[part 1 of 3: packages /Nexteer/NvMProxy_swc/DataTypes to /Nexteer/NvMProxy_swc/ComponentTypes]
AUTOSAR XML (schema 4-1-2)
package /Nexteer/NvMProxy_swc/DataTypes
  impl type NvM_BlockIdType: category=VALUE, base-type=NvM_BlockIdType, range raw 1..32767
  impl type NvM_RequestResultType: category=VALUE, base-type=NvM_RequestResultType, compu {0=NVM_REQ_OK, 1=NVM_REQ_NOT_OK, 2=NVM_REQ_PENDING, 3=NVM_REQ_INTEGRITY_FAILED, 4=NVM_REQ_BLOCK_SKIPPED, 5=NVM_REQ_NV_INVALIDATED, 6=NVM_REQ_CANCELED, 7=NVM_REQ_REDUNDANCY_FAILED, 8=NVM_REQ_RESTORED_FROM_ROM}
package /Nexteer/NvMProxy_swc/DataTypes/BaseTypes
  base type NvM_BlockIdType: category=FIXED_LENGTH, base-type-size=16, base-type-encoding=NONE, native-declaration=uint16
  base type NvM_RequestResultType: category=FIXED_LENGTH, base-type-size=8, base-type-encoding=NONE, native-declaration=uint8
package /Nexteer/NvMProxy_swc/Interfaces
  5 x client server interface, all with is-service=true:
    NvMAdministration
      operation SetBlockProtection: possible-error=NvMAdministration/E_NOT_OK
        arg ProtectionEnabled_Arg: type=boolean, direction=IN
      error E_NOT_OK: error-code=1
    NvMService_AC3_SRBS
      6 x operation, all with possible-error=NvMService_AC3_SRBS/E_NOT_OK:
        EraseBlock
        GetErrorStatus
          arg ErrorStatus_Arg: type=NvM_RequestResultType, direction=OUT
        InvalidateNvBlock
        ReadBlock
          arg DstPtr_Arg: type=dtRef_VOID, direction=IN
        SetRamBlockStatus
          arg RamBlockStatus_Arg: type=boolean, direction=IN
        WriteBlock
          arg SrcPtr_Arg: type=dtRef_const_VOID, direction=IN
      error E_NOT_OK: error-code=1
    NvMService_AC3_SRBS_Defs
      7 x operation, all with possible-error=NvMService_AC3_SRBS_Defs/E_NOT_OK:
        EraseBlock
        GetErrorStatus
          arg ErrorStatus_Arg: type=NvM_RequestResultType, direction=OUT
        InvalidateNvBlock
        ReadBlock
          arg DstPtr_Arg: type=dtRef_VOID, direction=IN
        RestoreBlockDefaults
          arg DstPtr_Arg: type=dtRef_VOID, direction=IN
        SetRamBlockStatus
          arg RamBlockStatus_Arg: type=boolean, direction=IN
        WriteBlock
          arg SrcPtr_Arg: type=dtRef_const_VOID, direction=IN
      error E_NOT_OK: error-code=1
    NvMService_AC3_SRBS_DS
      8 x operation, all with possible-error=NvMService_AC3_SRBS_DS/E_NOT_OK:
        EraseBlock
        GetDataIndex
          arg DataIndex_Arg: type=uint8, direction=OUT
        GetErrorStatus
          arg ErrorStatus_Arg: type=NvM_RequestResultType, direction=OUT
        InvalidateNvBlock
        ReadBlock
          arg DstPtr_Arg: type=dtRef_VOID, direction=IN
        SetDataIndex
          arg DataIndex_Arg: type=uint8, direction=IN
        SetRamBlockStatus
          arg RamBlockStatus_Arg: type=boolean, direction=IN
        WriteBlock
          arg SrcPtr_Arg: type=dtRef_const_VOID, direction=IN
      error E_NOT_OK: error-code=1
    NvMService_AC3_SRBS_DS_Defs
      9 x operation, all with possible-error=NvMService_AC3_SRBS_DS_Defs/E_NOT_OK:
        EraseBlock
        GetDataIndex
          arg DataIndex_Arg: type=uint8, direction=OUT
        GetErrorStatus
          arg ErrorStatus_Arg: type=NvM_RequestResultType, direction=OUT
        InvalidateNvBlock
        ReadBlock
          arg DstPtr_Arg: type=dtRef_VOID, direction=IN
        RestoreBlockDefaults
          arg DstPtr_Arg: type=dtRef_VOID, direction=IN
        SetDataIndex
          arg DataIndex_Arg: type=uint8, direction=IN
        SetRamBlockStatus
          arg RamBlockStatus_Arg: type=boolean, direction=IN
        WriteBlock
          arg SrcPtr_Arg: type=dtRef_const_VOID, direction=IN
      error E_NOT_OK: error-code=1
package /Nexteer/NvMProxy_swc/ComponentTypes
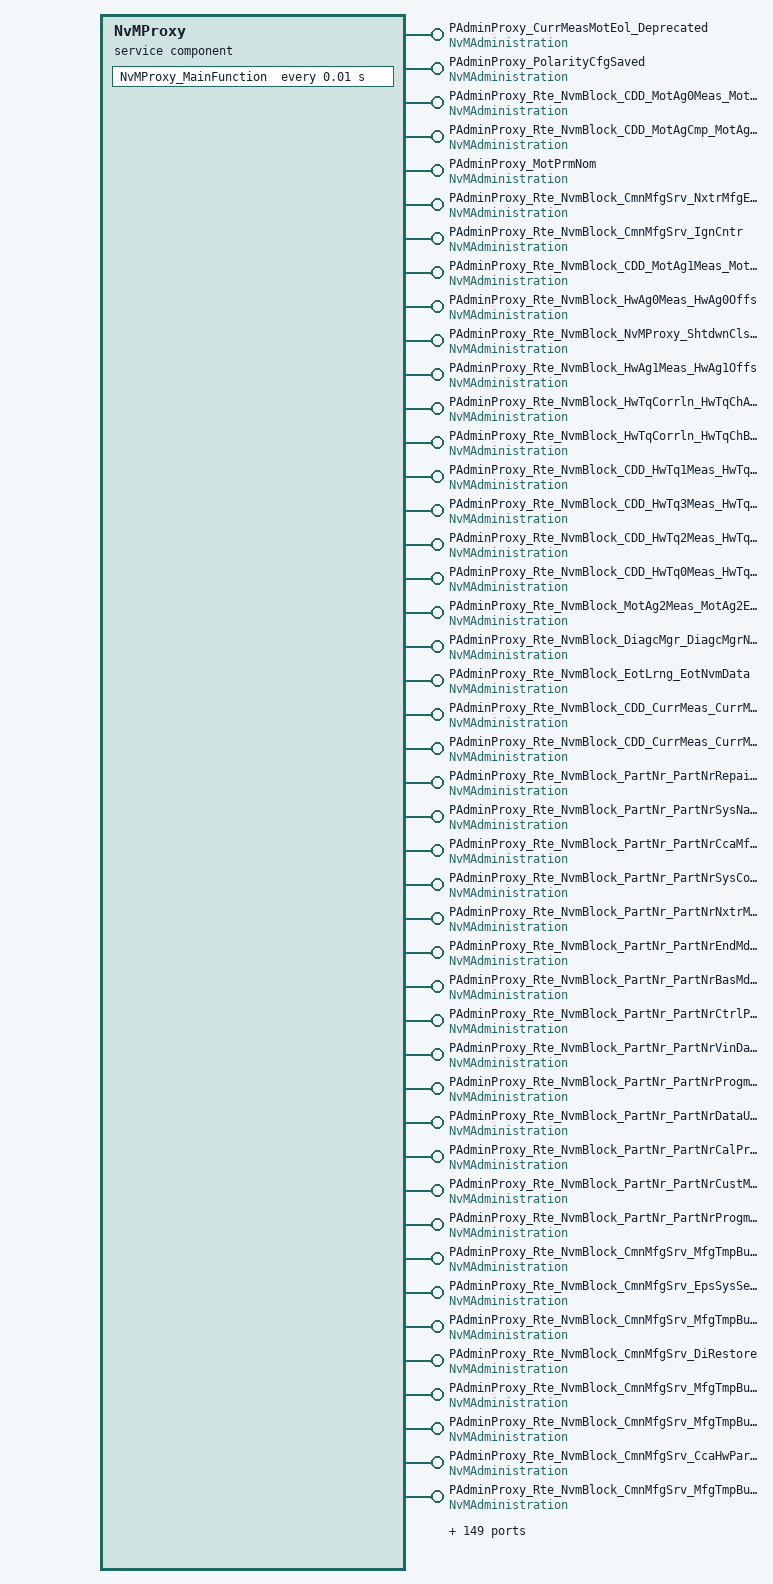
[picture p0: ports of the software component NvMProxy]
  service sw component type NvMProxy
    232 x provide port:
      PAdminProxy_CurrMeasMotEol_Deprecated: server-com-spec{operation=SetBlockProtection, queue-length=1}, provided-interface=NvMAdministration
      PAdminProxy_PolarityCfgSaved: server-com-spec{operation=SetBlockProtection, queue-length=1}, provided-interface=NvMAdministration
      PAdminProxy_Rte_NvmBlock_CDD_MotAg0Meas_MotAg0CoeffTbl: server-com-spec{operation=SetBlockProtection, queue-length=1}, provided-interface=NvMAdministration
      PAdminProxy_Rte_NvmBlock_CDD_MotAgCmp_MotAgCmpMotAgBackEmf: server-com-spec{operation=SetBlockProtection, queue-length=1}, provided-interface=NvMAdministration
      PAdminProxy_MotPrmNom: server-com-spec{operation=SetBlockProtection, queue-length=1}, provided-interface=NvMAdministration
      PAdminProxy_Rte_NvmBlock_CmnMfgSrv_NxtrMfgEnaCntr: server-com-spec{operation=SetBlockProtection, queue-length=1}, provided-interface=NvMAdministration
      PAdminProxy_Rte_NvmBlock_CmnMfgSrv_IgnCntr: server-com-spec{operation=SetBlockProtection, queue-length=1}, provided-interface=NvMAdministration
      PAdminProxy_Rte_NvmBlock_CDD_MotAg1Meas_MotAg1CoeffTbl: server-com-spec{operation=SetBlockProtection, queue-length=1}, provided-interface=NvMAdministration
      PAdminProxy_Rte_NvmBlock_HwAg0Meas_HwAg0Offs: server-com-spec{operation=SetBlockProtection, queue-length=1}, provided-interface=NvMAdministration
      PAdminProxy_Rte_NvmBlock_NvMProxy_ShtdwnClsChk: server-com-spec{operation=SetBlockProtection, queue-length=1}, provided-interface=NvMAdministration
      PAdminProxy_Rte_NvmBlock_HwAg1Meas_HwAg1Offs: server-com-spec{operation=SetBlockProtection, queue-length=1}, provided-interface=NvMAdministration
      PAdminProxy_Rte_NvmBlock_HwTqCorrln_HwTqChACmnModCmpLpFilSt: server-com-spec{operation=SetBlockProtection, queue-length=1}, provided-interface=NvMAdministration
      PAdminProxy_Rte_NvmBlock_HwTqCorrln_HwTqChBCmnModCmpLpFilSt: server-com-spec{operation=SetBlockProtection, queue-length=1}, provided-interface=NvMAdministration
      PAdminProxy_Rte_NvmBlock_CDD_HwTq1Meas_HwTq1Offs: server-com-spec{operation=SetBlockProtection, queue-length=1}, provided-interface=NvMAdministration
      PAdminProxy_Rte_NvmBlock_CDD_HwTq3Meas_HwTq3Offs: server-com-spec{operation=SetBlockProtection, queue-length=1}, provided-interface=NvMAdministration
      PAdminProxy_Rte_NvmBlock_CDD_HwTq2Meas_HwTq2Offs: server-com-spec{operation=SetBlockProtection, queue-length=1}, provided-interface=NvMAdministration
      PAdminProxy_Rte_NvmBlock_CDD_HwTq0Meas_HwTq0Offs: server-com-spec{operation=SetBlockProtection, queue-length=1}, provided-interface=NvMAdministration
      PAdminProxy_Rte_NvmBlock_MotAg2Meas_MotAg2EolPrm: server-com-spec{operation=SetBlockProtection, queue-length=1}, provided-interface=NvMAdministration
      PAdminProxy_Rte_NvmBlock_DiagcMgr_DiagcMgrNtcFltAry: server-com-spec{operation=SetBlockProtection, queue-length=1}, provided-interface=NvMAdministration
      PAdminProxy_Rte_NvmBlock_EotLrng_EotNvmData: server-com-spec{operation=SetBlockProtection, queue-length=1}, provided-interface=NvMAdministration
      PAdminProxy_Rte_NvmBlock_CDD_CurrMeas_CurrMeasEolOffsCalSet: server-com-spec{operation=SetBlockProtection, queue-length=1}, provided-interface=NvMAdministration
      PAdminProxy_Rte_NvmBlock_CDD_CurrMeas_CurrMeasEolGainCalSet: server-com-spec{operation=SetBlockProtection, queue-length=1}, provided-interface=NvMAdministration
      PAdminProxy_Rte_NvmBlock_PartNr_PartNrRepairShopCod: server-com-spec{operation=SetBlockProtection, queue-length=1}, provided-interface=NvMAdministration
      PAdminProxy_Rte_NvmBlock_PartNr_PartNrSysName: server-com-spec{operation=SetBlockProtection, queue-length=1}, provided-interface=NvMAdministration
      PAdminProxy_Rte_NvmBlock_PartNr_PartNrCcaMfgTrakg: server-com-spec{operation=SetBlockProtection, queue-length=1}, provided-interface=NvMAdministration
      PAdminProxy_Rte_NvmBlock_PartNr_PartNrSysCodVersNr: server-com-spec{operation=SetBlockProtection, queue-length=1}, provided-interface=NvMAdministration
      PAdminProxy_Rte_NvmBlock_PartNr_PartNrNxtrMfgTrakg: server-com-spec{operation=SetBlockProtection, queue-length=1}, provided-interface=NvMAdministration
      PAdminProxy_Rte_NvmBlock_PartNr_PartNrEndMdlPartNr: server-com-spec{operation=SetBlockProtection, queue-length=1}, provided-interface=NvMAdministration
      PAdminProxy_Rte_NvmBlock_PartNr_PartNrBasMdlPartNr: server-com-spec{operation=SetBlockProtection, queue-length=1}, provided-interface=NvMAdministration
      PAdminProxy_Rte_NvmBlock_PartNr_PartNrCtrlPidSeedKey: server-com-spec{operation=SetBlockProtection, queue-length=1}, provided-interface=NvMAdministration
      PAdminProxy_Rte_NvmBlock_PartNr_PartNrVinData: server-com-spec{operation=SetBlockProtection, queue-length=1}, provided-interface=NvMAdministration
      PAdminProxy_Rte_NvmBlock_PartNr_PartNrProgmDate: server-com-spec{operation=SetBlockProtection, queue-length=1}, provided-interface=NvMAdministration
      PAdminProxy_Rte_NvmBlock_PartNr_PartNrDataUniversalNrSysId: server-com-spec{operation=SetBlockProtection, queue-length=1}, provided-interface=NvMAdministration
      PAdminProxy_Rte_NvmBlock_PartNr_PartNrCalProgdSts: server-com-spec{operation=SetBlockProtection, queue-length=1}, provided-interface=NvMAdministration
      PAdminProxy_Rte_NvmBlock_PartNr_PartNrCustMfgEnaCntr: server-com-spec{operation=SetBlockProtection, queue-length=1}, provided-interface=NvMAdministration
      PAdminProxy_Rte_NvmBlock_PartNr_PartNrProgmSessionSeedKey: server-com-spec{operation=SetBlockProtection, queue-length=1}, provided-interface=NvMAdministration
      PAdminProxy_Rte_NvmBlock_CmnMfgSrv_MfgTmpBuf4: server-com-spec{operation=SetBlockProtection, queue-length=1}, provided-interface=NvMAdministration
      PAdminProxy_Rte_NvmBlock_CmnMfgSrv_EpsSysSerlNr: server-com-spec{operation=SetBlockProtection, queue-length=1}, provided-interface=NvMAdministration
      PAdminProxy_Rte_NvmBlock_CmnMfgSrv_MfgTmpBuf3: server-com-spec{operation=SetBlockProtection, queue-length=1}, provided-interface=NvMAdministration
      PAdminProxy_Rte_NvmBlock_CmnMfgSrv_DiRestore: server-com-spec{operation=SetBlockProtection, queue-length=1}, provided-interface=NvMAdministration
      PAdminProxy_Rte_NvmBlock_CmnMfgSrv_MfgTmpBuf2: server-com-spec{operation=SetBlockProtection, queue-length=1}, provided-interface=NvMAdministration
      PAdminProxy_Rte_NvmBlock_CmnMfgSrv_MfgTmpBuf1: server-com-spec{operation=SetBlockProtection, queue-length=1}, provided-interface=NvMAdministration
      PAdminProxy_Rte_NvmBlock_CmnMfgSrv_CcaHwPartNr: server-com-spec{operation=SetBlockProtection, queue-length=1}, provided-interface=NvMAdministration
      PAdminProxy_Rte_NvmBlock_CmnMfgSrv_MfgTmpBuf0: server-com-spec{operation=SetBlockProtection, queue-length=1}, provided-interface=NvMAdministration
      PAdminProxy_Rte_NvmBlock_CmnMfgSrv_CcaSerlNr: server-com-spec{operation=SetBlockProtection, queue-length=1}, provided-interface=NvMAdministration
      PAdminProxy_Rte_NvmBlock_DutyCycThermProtn_FilStVal: server-com-spec{operation=SetBlockProtection, queue-length=1}, provided-interface=NvMAdministration
      PAdminProxy_Rte_NvmBlock_PullCmpActv_PullCmpLongTerm: server-com-spec{operation=SetBlockProtection, queue-length=1}, provided-interface=NvMAdministration
      PAdminProxy_Rte_NvmBlock_MotTqCmdSca_MotTqScaFac: server-com-spec{operation=SetBlockProtection, queue-length=1}, provided-interface=NvMAdministration
      PAdminProxy_Rte_NvmBlock_SnsrOffsLrng_SnsrOffsLrnd: server-com-spec{operation=SetBlockProtection, queue-length=1}, provided-interface=NvMAdministration
      PAdminProxy_Rte_NvmBlock_GmOvrlStMgr_GmLoaIgnCntr: server-com-spec{operation=SetBlockProtection, queue-length=1}, provided-interface=NvMAdministration
      PAdminProxy_Rte_NvmBlock_MotRplCoggCfg_MotRplCoggPrm: server-com-spec{operation=SetBlockProtection, queue-length=1}, provided-interface=NvMAdministration
      PAdminProxy_Rte_NvmBlock_CDD_MotRplCoggCmd_MotCoggCmdY: server-com-spec{operation=SetBlockProtection, queue-length=1}, provided-interface=NvMAdministration
      PAdminProxy_Rte_NvmBlock_StHlthSigStc_SigStcHistDataAry: server-com-spec{operation=SetBlockProtection, queue-length=1}, provided-interface=NvMAdministration
      PAdminProxy_Rte_NvmBlock_HwAgVehCentrTrim_HwAgTrimVal_Deprecated: server-com-spec{operation=SetBlockProtection, queue-length=1}, provided-interface=NvMAdministration
      PAdminProxy_Rte_NvmBlock_WhlImbRejctn_MaxCompPerc_Deprecated: server-com-spec{operation=SetBlockProtection, queue-length=1}, provided-interface=NvMAdministration
      PAdminProxy_Rte_NvmBlock_WhlImbRejctn_ActvCmpBand3_Deprecated: server-com-spec{operation=SetBlockProtection, queue-length=1}, provided-interface=NvMAdministration
      PAdminProxy_Rte_NvmBlock_WhlImbRejctn_ActvCmpBand1_Deprecated: server-com-spec{operation=SetBlockProtection, queue-length=1}, provided-interface=NvMAdministration
      PAdminProxy_Rte_NvmBlock_WhlImbRejctn_RiPeakPrev_Deprecated: server-com-spec{operation=SetBlockProtection, queue-length=1}, provided-interface=NvMAdministration
      PAdminProxy_Rte_NvmBlock_WhlImbRejctn_LePeakPrev_Deprecated: server-com-spec{operation=SetBlockProtection, queue-length=1}, provided-interface=NvMAdministration
      PAdminProxy_Rte_NvmBlock_WhlImbRejctn_ActvCmpBand2_Deprecated: server-com-spec{operation=SetBlockProtection, queue-length=1}, provided-interface=NvMAdministration
      PAdminProxy_Rte_NvmBlock_HwAgVehCentrTrim_HwAgTrimData: server-com-spec{operation=SetBlockProtection, queue-length=1}, provided-interface=NvMAdministration
      PAdminProxy_Rte_NvmBlock_SysFricLrng_FricNonLrngData: server-com-spec{operation=SetBlockProtection, queue-length=1}, provided-interface=NvMAdministration
      PAdminProxy_Rte_NvmBlock_SysFricLrng_FricLrngData: server-com-spec{operation=SetBlockProtection, queue-length=1}, provided-interface=NvMAdministration
      PAdminProxy_Rte_NvmBlock_Bootloader_EcuId: server-com-spec{operation=SetBlockProtection, queue-length=1}, provided-interface=NvMAdministration
      PAdminProxy_Rte_NvmBlock_Bootloader_NbId: server-com-spec{operation=SetBlockProtection, queue-length=1}, provided-interface=NvMAdministration
      PAdminProxy_Rte_NvmBlock_Bootloader_SBAT: server-com-spec{operation=SetBlockProtection, queue-length=1}, provided-interface=NvMAdministration
      PAdminProxy_DemAdminDataBlock: server-com-spec{operation=SetBlockProtection, queue-length=1}, provided-interface=NvMAdministration
      PAdminProxy_DemStatusDataBlock: server-com-spec{operation=SetBlockProtection, queue-length=1}, provided-interface=NvMAdministration
      PAdminProxy_DemPrimaryDataBlock{0..39}: server-com-spec{operation=SetBlockProtection, queue-length=1}, provided-interface=NvMAdministration
      PAdminProxy_Rte_NvmBlock_CustDiagc_GmIgnCntr: server-com-spec{operation=SetBlockProtection, queue-length=1}, provided-interface=NvMAdministration
      PAdminProxy_Rte_NvmBlock_GmMsg778BusHiSpd_DtcTrigStsAry: server-com-spec{operation=SetBlockProtection, queue-length=1}, provided-interface=NvMAdministration
      PAdminProxy_SnpshtDataAry: server-com-spec{operation=SetBlockProtection, queue-length=1}, provided-interface=NvMAdministration
      PAdminProxy_Rte_NvmBlock_HwAgSnsrls_StordLstPrm: server-com-spec{operation=SetBlockProtection, queue-length=1}, provided-interface=NvMAdministration
      PAdminProxy_Rte_NvmBlock_EotLrng_MaxHwAgCwAndCcw_Deprecated: server-com-spec{operation=SetBlockProtection, queue-length=1}, provided-interface=NvMAdministration
      PAdminProxy_Rte_NvmBlock_CmnMfgSrv_SeedKey: server-com-spec{operation=SetBlockProtection, queue-length=1}, provided-interface=NvMAdministration
      PAdminProxy_Rte_NvmBlock_EotLrng_MaxHwAgCwAndCcw: server-com-spec{operation=SetBlockProtection, queue-length=1}, provided-interface=NvMAdministration
      PAdminProxy_Rte_NvmBlock_WhlImbRejctn_CmpPeakData: server-com-spec{operation=SetBlockProtection, queue-length=1}, provided-interface=NvMAdministration
      PSProxy_Rte_NvmBlock_CDD_MotAg0Meas_MotAg0CoeffTbl: provided-interface=NvMService_AC3_SRBS_Defs
        provided-com-specs:
          operation=NvMService_AC3_SRBS_Defs/EraseBlock, queue-length=1
          operation=NvMService_AC3_SRBS_Defs/GetErrorStatus, queue-length=1
          operation=NvMService_AC3_SRBS_Defs/InvalidateNvBlock, queue-length=1
          operation=NvMService_AC3_SRBS_Defs/ReadBlock, queue-length=1
          operation=NvMService_AC3_SRBS_Defs/RestoreBlockDefaults, queue-length=1
          operation=NvMService_AC3_SRBS_Defs/SetRamBlockStatus, queue-length=1
          operation=NvMService_AC3_SRBS_Defs/WriteBlock, queue-length=1
      PSProxy_Rte_NvmBlock_CDD_MotAgCmp_MotAgCmpMotAgBackEmf: provided-interface=NvMService_AC3_SRBS_Defs
        provided-com-specs:
          operation=NvMService_AC3_SRBS_Defs/EraseBlock, queue-length=1
          operation=NvMService_AC3_SRBS_Defs/GetErrorStatus, queue-length=1
          operation=NvMService_AC3_SRBS_Defs/InvalidateNvBlock, queue-length=1
          operation=NvMService_AC3_SRBS_Defs/ReadBlock, queue-length=1
          operation=NvMService_AC3_SRBS_Defs/RestoreBlockDefaults, queue-length=1
          operation=NvMService_AC3_SRBS_Defs/SetRamBlockStatus, queue-length=1
          operation=NvMService_AC3_SRBS_Defs/WriteBlock, queue-length=1
      PSProxy_Rte_NvmBlock_CmnMfgSrv_NxtrMfgEnaCntr: provided-interface=NvMService_AC3_SRBS_Defs
        provided-com-specs:
          operation=NvMService_AC3_SRBS_Defs/EraseBlock, queue-length=1
          operation=NvMService_AC3_SRBS_Defs/GetErrorStatus, queue-length=1
          operation=NvMService_AC3_SRBS_Defs/InvalidateNvBlock, queue-length=1
          operation=NvMService_AC3_SRBS_Defs/ReadBlock, queue-length=1
          operation=NvMService_AC3_SRBS_Defs/RestoreBlockDefaults, queue-length=1
          operation=NvMService_AC3_SRBS_Defs/SetRamBlockStatus, queue-length=1
          operation=NvMService_AC3_SRBS_Defs/WriteBlock, queue-length=1
      PSProxy_Rte_NvmBlock_CmnMfgSrv_IgnCntr: provided-interface=NvMService_AC3_SRBS_Defs
        provided-com-specs:
          operation=NvMService_AC3_SRBS_Defs/EraseBlock, queue-length=1
          operation=NvMService_AC3_SRBS_Defs/GetErrorStatus, queue-length=1
          operation=NvMService_AC3_SRBS_Defs/InvalidateNvBlock, queue-length=1
          operation=NvMService_AC3_SRBS_Defs/ReadBlock, queue-length=1
          operation=NvMService_AC3_SRBS_Defs/RestoreBlockDefaults, queue-length=1
          operation=NvMService_AC3_SRBS_Defs/SetRamBlockStatus, queue-length=1
          operation=NvMService_AC3_SRBS_Defs/WriteBlock, queue-length=1
      PSProxy_Rte_NvmBlock_CDD_MotAg1Meas_MotAg1CoeffTbl: provided-interface=NvMService_AC3_SRBS_Defs
        provided-com-specs:
          operation=NvMService_AC3_SRBS_Defs/EraseBlock, queue-length=1
          operation=NvMService_AC3_SRBS_Defs/GetErrorStatus, queue-length=1
          operation=NvMService_AC3_SRBS_Defs/InvalidateNvBlock, queue-length=1
          operation=NvMService_AC3_SRBS_Defs/ReadBlock, queue-length=1
          operation=NvMService_AC3_SRBS_Defs/RestoreBlockDefaults, queue-length=1
          operation=NvMService_AC3_SRBS_Defs/SetRamBlockStatus, queue-length=1
          operation=NvMService_AC3_SRBS_Defs/WriteBlock, queue-length=1
      PSProxy_Rte_NvmBlock_HwAg0Meas_HwAg0Offs: provided-interface=NvMService_AC3_SRBS_Defs
        provided-com-specs:
          operation=NvMService_AC3_SRBS_Defs/EraseBlock, queue-length=1
          operation=NvMService_AC3_SRBS_Defs/GetErrorStatus, queue-length=1
          operation=NvMService_AC3_SRBS_Defs/InvalidateNvBlock, queue-length=1
          operation=NvMService_AC3_SRBS_Defs/ReadBlock, queue-length=1
          operation=NvMService_AC3_SRBS_Defs/RestoreBlockDefaults, queue-length=1
          operation=NvMService_AC3_SRBS_Defs/SetRamBlockStatus, queue-length=1
          operation=NvMService_AC3_SRBS_Defs/WriteBlock, queue-length=1
      PSProxy_Rte_NvmBlock_HwAg1Meas_HwAg1Offs: provided-interface=NvMService_AC3_SRBS_Defs
        provided-com-specs:
          operation=NvMService_AC3_SRBS_Defs/EraseBlock, queue-length=1
          operation=NvMService_AC3_SRBS_Defs/GetErrorStatus, queue-length=1
          operation=NvMService_AC3_SRBS_Defs/InvalidateNvBlock, queue-length=1
          operation=NvMService_AC3_SRBS_Defs/ReadBlock, queue-length=1
          operation=NvMService_AC3_SRBS_Defs/RestoreBlockDefaults, queue-length=1
          operation=NvMService_AC3_SRBS_Defs/SetRamBlockStatus, queue-length=1
          operation=NvMService_AC3_SRBS_Defs/WriteBlock, queue-length=1
      PSProxy_Rte_NvmBlock_HwTqCorrln_HwTqChACmnModCmpLpFilSt: provided-interface=NvMService_AC3_SRBS_Defs
        provided-com-specs:
          operation=NvMService_AC3_SRBS_Defs/EraseBlock, queue-length=1
          operation=NvMService_AC3_SRBS_Defs/GetErrorStatus, queue-length=1
          operation=NvMService_AC3_SRBS_Defs/InvalidateNvBlock, queue-length=1
          operation=NvMService_AC3_SRBS_Defs/ReadBlock, queue-length=1
          operation=NvMService_AC3_SRBS_Defs/RestoreBlockDefaults, queue-length=1
          operation=NvMService_AC3_SRBS_Defs/SetRamBlockStatus, queue-length=1
          operation=NvMService_AC3_SRBS_Defs/WriteBlock, queue-length=1
      PSProxy_Rte_NvmBlock_HwTqCorrln_HwTqChBCmnModCmpLpFilSt: provided-interface=NvMService_AC3_SRBS_Defs
        provided-com-specs:
          operation=NvMService_AC3_SRBS_Defs/EraseBlock, queue-length=1
          operation=NvMService_AC3_SRBS_Defs/GetErrorStatus, queue-length=1
          operation=NvMService_AC3_SRBS_Defs/InvalidateNvBlock, queue-length=1
          operation=NvMService_AC3_SRBS_Defs/ReadBlock, queue-length=1
          operation=NvMService_AC3_SRBS_Defs/RestoreBlockDefaults, queue-length=1
          operation=NvMService_AC3_SRBS_Defs/SetRamBlockStatus, queue-length=1
          operation=NvMService_AC3_SRBS_Defs/WriteBlock, queue-length=1
      PSProxy_Rte_NvmBlock_CDD_HwTq1Meas_HwTq1Offs: provided-interface=NvMService_AC3_SRBS_Defs
        provided-com-specs:
          operation=NvMService_AC3_SRBS_Defs/EraseBlock, queue-length=1
          operation=NvMService_AC3_SRBS_Defs/GetErrorStatus, queue-length=1
          operation=NvMService_AC3_SRBS_Defs/InvalidateNvBlock, queue-length=1
          operation=NvMService_AC3_SRBS_Defs/ReadBlock, queue-length=1
          operation=NvMService_AC3_SRBS_Defs/RestoreBlockDefaults, queue-length=1
          operation=NvMService_AC3_SRBS_Defs/SetRamBlockStatus, queue-length=1
          operation=NvMService_AC3_SRBS_Defs/WriteBlock, queue-length=1
      PSProxy_Rte_NvmBlock_CDD_HwTq3Meas_HwTq3Offs: provided-interface=NvMService_AC3_SRBS_Defs
        provided-com-specs:
          operation=NvMService_AC3_SRBS_Defs/EraseBlock, queue-length=1
          operation=NvMService_AC3_SRBS_Defs/GetErrorStatus, queue-length=1
          operation=NvMService_AC3_SRBS_Defs/InvalidateNvBlock, queue-length=1
          operation=NvMService_AC3_SRBS_Defs/ReadBlock, queue-length=1
          operation=NvMService_AC3_SRBS_Defs/RestoreBlockDefaults, queue-length=1
          operation=NvMService_AC3_SRBS_Defs/SetRamBlockStatus, queue-length=1
          operation=NvMService_AC3_SRBS_Defs/WriteBlock, queue-length=1
      PSProxy_Rte_NvmBlock_CDD_HwTq2Meas_HwTq2Offs: provided-interface=NvMService_AC3_SRBS_Defs
        provided-com-specs:
          operation=NvMService_AC3_SRBS_Defs/EraseBlock, queue-length=1
          operation=NvMService_AC3_SRBS_Defs/GetErrorStatus, queue-length=1
          operation=NvMService_AC3_SRBS_Defs/InvalidateNvBlock, queue-length=1
          operation=NvMService_AC3_SRBS_Defs/ReadBlock, queue-length=1
          operation=NvMService_AC3_SRBS_Defs/RestoreBlockDefaults, queue-length=1
          operation=NvMService_AC3_SRBS_Defs/SetRamBlockStatus, queue-length=1
          operation=NvMService_AC3_SRBS_Defs/WriteBlock, queue-length=1
      PSProxy_Rte_NvmBlock_CDD_HwTq0Meas_HwTq0Offs: provided-interface=NvMService_AC3_SRBS_Defs
        provided-com-specs:
          operation=NvMService_AC3_SRBS_Defs/EraseBlock, queue-length=1
          operation=NvMService_AC3_SRBS_Defs/GetErrorStatus, queue-length=1
          operation=NvMService_AC3_SRBS_Defs/InvalidateNvBlock, queue-length=1
          operation=NvMService_AC3_SRBS_Defs/ReadBlock, queue-length=1
          operation=NvMService_AC3_SRBS_Defs/RestoreBlockDefaults, queue-length=1
          operation=NvMService_AC3_SRBS_Defs/SetRamBlockStatus, queue-length=1
          operation=NvMService_AC3_SRBS_Defs/WriteBlock, queue-length=1
      PSProxy_Rte_NvmBlock_MotAg2Meas_MotAg2EolPrm: provided-interface=NvMService_AC3_SRBS_Defs
        provided-com-specs:
          operation=NvMService_AC3_SRBS_Defs/EraseBlock, queue-length=1
          operation=NvMService_AC3_SRBS_Defs/GetErrorStatus, queue-length=1
          operation=NvMService_AC3_SRBS_Defs/InvalidateNvBlock, queue-length=1
          operation=NvMService_AC3_SRBS_Defs/ReadBlock, queue-length=1
          operation=NvMService_AC3_SRBS_Defs/RestoreBlockDefaults, queue-length=1
          operation=NvMService_AC3_SRBS_Defs/SetRamBlockStatus, queue-length=1
          operation=NvMService_AC3_SRBS_Defs/WriteBlock, queue-length=1
      PSProxy_Rte_NvmBlock_EotLrng_EotNvmData: provided-interface=NvMService_AC3_SRBS_Defs
        provided-com-specs:
          operation=NvMService_AC3_SRBS_Defs/EraseBlock, queue-length=1
          operation=NvMService_AC3_SRBS_Defs/GetErrorStatus, queue-length=1
          operation=NvMService_AC3_SRBS_Defs/InvalidateNvBlock, queue-length=1
          operation=NvMService_AC3_SRBS_Defs/ReadBlock, queue-length=1
          operation=NvMService_AC3_SRBS_Defs/RestoreBlockDefaults, queue-length=1
          operation=NvMService_AC3_SRBS_Defs/SetRamBlockStatus, queue-length=1
          operation=NvMService_AC3_SRBS_Defs/WriteBlock, queue-length=1
      PSProxy_Rte_NvmBlock_CDD_CurrMeas_CurrMeasEolOffsCalSet: provided-interface=NvMService_AC3_SRBS_Defs
        provided-com-specs:
          operation=NvMService_AC3_SRBS_Defs/EraseBlock, queue-length=1
          operation=NvMService_AC3_SRBS_Defs/GetErrorStatus, queue-length=1
          operation=NvMService_AC3_SRBS_Defs/InvalidateNvBlock, queue-length=1
          operation=NvMService_AC3_SRBS_Defs/ReadBlock, queue-length=1
          operation=NvMService_AC3_SRBS_Defs/RestoreBlockDefaults, queue-length=1
          operation=NvMService_AC3_SRBS_Defs/SetRamBlockStatus, queue-length=1
          operation=NvMService_AC3_SRBS_Defs/WriteBlock, queue-length=1
      PSProxy_Rte_NvmBlock_CDD_CurrMeas_CurrMeasEolGainCalSet: provided-interface=NvMService_AC3_SRBS_Defs
        provided-com-specs:
          operation=NvMService_AC3_SRBS_Defs/EraseBlock, queue-length=1
          operation=NvMService_AC3_SRBS_Defs/GetErrorStatus, queue-length=1
          operation=NvMService_AC3_SRBS_Defs/InvalidateNvBlock, queue-length=1
          operation=NvMService_AC3_SRBS_Defs/ReadBlock, queue-length=1
          operation=NvMService_AC3_SRBS_Defs/RestoreBlockDefaults, queue-length=1
          operation=NvMService_AC3_SRBS_Defs/SetRamBlockStatus, queue-length=1
          operation=NvMService_AC3_SRBS_Defs/WriteBlock, queue-length=1
      PSProxy_Rte_NvmBlock_PartNr_PartNrRepairShopCod: provided-interface=NvMService_AC3_SRBS_Defs
        provided-com-specs:
          operation=NvMService_AC3_SRBS_Defs/EraseBlock, queue-length=1
          operation=NvMService_AC3_SRBS_Defs/GetErrorStatus, queue-length=1
          operation=NvMService_AC3_SRBS_Defs/InvalidateNvBlock, queue-length=1
          operation=NvMService_AC3_SRBS_Defs/ReadBlock, queue-length=1
          operation=NvMService_AC3_SRBS_Defs/RestoreBlockDefaults, queue-length=1
          operation=NvMService_AC3_SRBS_Defs/SetRamBlockStatus, queue-length=1
          operation=NvMService_AC3_SRBS_Defs/WriteBlock, queue-length=1
      PSProxy_Rte_NvmBlock_PartNr_PartNrSysName: provided-interface=NvMService_AC3_SRBS_Defs
        provided-com-specs:
          operation=NvMService_AC3_SRBS_Defs/EraseBlock, queue-length=1
          operation=NvMService_AC3_SRBS_Defs/GetErrorStatus, queue-length=1
          operation=NvMService_AC3_SRBS_Defs/InvalidateNvBlock, queue-length=1
          operation=NvMService_AC3_SRBS_Defs/ReadBlock, queue-length=1
          operation=NvMService_AC3_SRBS_Defs/RestoreBlockDefaults, queue-length=1
          operation=NvMService_AC3_SRBS_Defs/SetRamBlockStatus, queue-length=1
          operation=NvMService_AC3_SRBS_Defs/WriteBlock, queue-length=1
      PSProxy_Rte_NvmBlock_PartNr_PartNrCcaMfgTrakg: provided-interface=NvMService_AC3_SRBS_Defs
        provided-com-specs:
          operation=NvMService_AC3_SRBS_Defs/EraseBlock, queue-length=1
          operation=NvMService_AC3_SRBS_Defs/GetErrorStatus, queue-length=1
          operation=NvMService_AC3_SRBS_Defs/InvalidateNvBlock, queue-length=1
          operation=NvMService_AC3_SRBS_Defs/ReadBlock, queue-length=1
          operation=NvMService_AC3_SRBS_Defs/RestoreBlockDefaults, queue-length=1
          operation=NvMService_AC3_SRBS_Defs/SetRamBlockStatus, queue-length=1
          operation=NvMService_AC3_SRBS_Defs/WriteBlock, queue-length=1
      PSProxy_Rte_NvmBlock_PartNr_PartNrSysCodVersNr: provided-interface=NvMService_AC3_SRBS_Defs
        provided-com-specs:
          operation=NvMService_AC3_SRBS_Defs/EraseBlock, queue-length=1
          operation=NvMService_AC3_SRBS_Defs/GetErrorStatus, queue-length=1
          operation=NvMService_AC3_SRBS_Defs/InvalidateNvBlock, queue-length=1
          operation=NvMService_AC3_SRBS_Defs/ReadBlock, queue-length=1
          operation=NvMService_AC3_SRBS_Defs/RestoreBlockDefaults, queue-length=1
          operation=NvMService_AC3_SRBS_Defs/SetRamBlockStatus, queue-length=1
          operation=NvMService_AC3_SRBS_Defs/WriteBlock, queue-length=1
      PSProxy_Rte_NvmBlock_PartNr_PartNrNxtrMfgTrakg: provided-interface=NvMService_AC3_SRBS_Defs
        provided-com-specs:
          operation=NvMService_AC3_SRBS_Defs/EraseBlock, queue-length=1
          operation=NvMService_AC3_SRBS_Defs/GetErrorStatus, queue-length=1
          operation=NvMService_AC3_SRBS_Defs/InvalidateNvBlock, queue-length=1
          operation=NvMService_AC3_SRBS_Defs/ReadBlock, queue-length=1
          operation=NvMService_AC3_SRBS_Defs/RestoreBlockDefaults, queue-length=1
          operation=NvMService_AC3_SRBS_Defs/SetRamBlockStatus, queue-length=1
          operation=NvMService_AC3_SRBS_Defs/WriteBlock, queue-length=1
      PSProxy_Rte_NvmBlock_PartNr_PartNrEndMdlPartNr: provided-interface=NvMService_AC3_SRBS_Defs
        provided-com-specs:
          operation=NvMService_AC3_SRBS_Defs/EraseBlock, queue-length=1
          operation=NvMService_AC3_SRBS_Defs/GetErrorStatus, queue-length=1
          operation=NvMService_AC3_SRBS_Defs/InvalidateNvBlock, queue-length=1
          operation=NvMService_AC3_SRBS_Defs/ReadBlock, queue-length=1
          operation=NvMService_AC3_SRBS_Defs/RestoreBlockDefaults, queue-length=1
          operation=NvMService_AC3_SRBS_Defs/SetRamBlockStatus, queue-length=1
          operation=NvMService_AC3_SRBS_Defs/WriteBlock, queue-length=1
      PSProxy_Rte_NvmBlock_PartNr_PartNrBasMdlPartNr: provided-interface=NvMService_AC3_SRBS_Defs
        provided-com-specs:
          operation=NvMService_AC3_SRBS_Defs/EraseBlock, queue-length=1
          operation=NvMService_AC3_SRBS_Defs/GetErrorStatus, queue-length=1
          operation=NvMService_AC3_SRBS_Defs/InvalidateNvBlock, queue-length=1
          operation=NvMService_AC3_SRBS_Defs/ReadBlock, queue-length=1
          operation=NvMService_AC3_SRBS_Defs/RestoreBlockDefaults, queue-length=1
          operation=NvMService_AC3_SRBS_Defs/SetRamBlockStatus, queue-length=1
          operation=NvMService_AC3_SRBS_Defs/WriteBlock, queue-length=1
      PSProxy_Rte_NvmBlock_PartNr_PartNrCtrlPidSeedKey: provided-interface=NvMService_AC3_SRBS_Defs
        provided-com-specs:
          operation=NvMService_AC3_SRBS_Defs/EraseBlock, queue-length=1
          operation=NvMService_AC3_SRBS_Defs/GetErrorStatus, queue-length=1
          operation=NvMService_AC3_SRBS_Defs/InvalidateNvBlock, queue-length=1
          operation=NvMService_AC3_SRBS_Defs/ReadBlock, queue-length=1
          operation=NvMService_AC3_SRBS_Defs/RestoreBlockDefaults, queue-length=1
          operation=NvMService_AC3_SRBS_Defs/SetRamBlockStatus, queue-length=1
          operation=NvMService_AC3_SRBS_Defs/WriteBlock, queue-length=1
      PSProxy_Rte_NvmBlock_PartNr_PartNrVinData: provided-interface=NvMService_AC3_SRBS_Defs
        provided-com-specs:
          operation=NvMService_AC3_SRBS_Defs/EraseBlock, queue-length=1
          operation=NvMService_AC3_SRBS_Defs/GetErrorStatus, queue-length=1
          operation=NvMService_AC3_SRBS_Defs/InvalidateNvBlock, queue-length=1
          operation=NvMService_AC3_SRBS_Defs/ReadBlock, queue-length=1
          operation=NvMService_AC3_SRBS_Defs/RestoreBlockDefaults, queue-length=1
          operation=NvMService_AC3_SRBS_Defs/SetRamBlockStatus, queue-length=1
          operation=NvMService_AC3_SRBS_Defs/WriteBlock, queue-length=1
      PSProxy_Rte_NvmBlock_PartNr_PartNrProgmDate: provided-interface=NvMService_AC3_SRBS_Defs
        provided-com-specs:
          operation=NvMService_AC3_SRBS_Defs/EraseBlock, queue-length=1
          operation=NvMService_AC3_SRBS_Defs/GetErrorStatus, queue-length=1
          operation=NvMService_AC3_SRBS_Defs/InvalidateNvBlock, queue-length=1
          operation=NvMService_AC3_SRBS_Defs/ReadBlock, queue-length=1
          operation=NvMService_AC3_SRBS_Defs/RestoreBlockDefaults, queue-length=1
          operation=NvMService_AC3_SRBS_Defs/SetRamBlockStatus, queue-length=1
          operation=NvMService_AC3_SRBS_Defs/WriteBlock, queue-length=1
      PSProxy_Rte_NvmBlock_PartNr_PartNrDataUniversalNrSysId: provided-interface=NvMService_AC3_SRBS_Defs
        provided-com-specs:
          operation=NvMService_AC3_SRBS_Defs/EraseBlock, queue-length=1
          operation=NvMService_AC3_SRBS_Defs/GetErrorStatus, queue-length=1
          operation=NvMService_AC3_SRBS_Defs/InvalidateNvBlock, queue-length=1
          operation=NvMService_AC3_SRBS_Defs/ReadBlock, queue-length=1
          operation=NvMService_AC3_SRBS_Defs/RestoreBlockDefaults, queue-length=1
          operation=NvMService_AC3_SRBS_Defs/SetRamBlockStatus, queue-length=1
          operation=NvMService_AC3_SRBS_Defs/WriteBlock, queue-length=1
      PSProxy_Rte_NvmBlock_PartNr_PartNrCalProgdSts: provided-interface=NvMService_AC3_SRBS_Defs
        provided-com-specs:
          operation=NvMService_AC3_SRBS_Defs/EraseBlock, queue-length=1
          operation=NvMService_AC3_SRBS_Defs/GetErrorStatus, queue-length=1
          operation=NvMService_AC3_SRBS_Defs/InvalidateNvBlock, queue-length=1
          operation=NvMService_AC3_SRBS_Defs/ReadBlock, queue-length=1
          operation=NvMService_AC3_SRBS_Defs/RestoreBlockDefaults, queue-length=1
          operation=NvMService_AC3_SRBS_Defs/SetRamBlockStatus, queue-length=1
          operation=NvMService_AC3_SRBS_Defs/WriteBlock, queue-length=1
      PSProxy_Rte_NvmBlock_PartNr_PartNrCustMfgEnaCntr: provided-interface=NvMService_AC3_SRBS_Defs
        provided-com-specs:
          operation=NvMService_AC3_SRBS_Defs/EraseBlock, queue-length=1
          operation=NvMService_AC3_SRBS_Defs/GetErrorStatus, queue-length=1
          operation=NvMService_AC3_SRBS_Defs/InvalidateNvBlock, queue-length=1
          operation=NvMService_AC3_SRBS_Defs/ReadBlock, queue-length=1
          operation=NvMService_AC3_SRBS_Defs/RestoreBlockDefaults, queue-length=1
          operation=NvMService_AC3_SRBS_Defs/SetRamBlockStatus, queue-length=1
          operation=NvMService_AC3_SRBS_Defs/WriteBlock, queue-length=1
      PSProxy_Rte_NvmBlock_PartNr_PartNrProgmSessionSeedKey: provided-interface=NvMService_AC3_SRBS_Defs
        provided-com-specs:
          operation=NvMService_AC3_SRBS_Defs/EraseBlock, queue-length=1
          operation=NvMService_AC3_SRBS_Defs/GetErrorStatus, queue-length=1
          operation=NvMService_AC3_SRBS_Defs/InvalidateNvBlock, queue-length=1
          operation=NvMService_AC3_SRBS_Defs/ReadBlock, queue-length=1
          operation=NvMService_AC3_SRBS_Defs/RestoreBlockDefaults, queue-length=1
          operation=NvMService_AC3_SRBS_Defs/SetRamBlockStatus, queue-length=1
          operation=NvMService_AC3_SRBS_Defs/WriteBlock, queue-length=1
      PSProxy_Rte_NvmBlock_PullCmpActv_PullCmpLongTerm: provided-interface=NvMService_AC3_SRBS_Defs
        provided-com-specs:
          operation=NvMService_AC3_SRBS_Defs/EraseBlock, queue-length=1
          operation=NvMService_AC3_SRBS_Defs/GetErrorStatus, queue-length=1
          operation=NvMService_AC3_SRBS_Defs/InvalidateNvBlock, queue-length=1
          operation=NvMService_AC3_SRBS_Defs/ReadBlock, queue-length=1
          operation=NvMService_AC3_SRBS_Defs/RestoreBlockDefaults, queue-length=1
          operation=NvMService_AC3_SRBS_Defs/SetRamBlockStatus, queue-length=1
          operation=NvMService_AC3_SRBS_Defs/WriteBlock, queue-length=1
      PSProxy_Rte_NvmBlock_HwAgVehCentrTrim_HwAgTrimData: provided-interface=NvMService_AC3_SRBS_Defs
        provided-com-specs:
          operation=NvMService_AC3_SRBS_Defs/EraseBlock, queue-length=1
          operation=NvMService_AC3_SRBS_Defs/GetErrorStatus, queue-length=1
          operation=NvMService_AC3_SRBS_Defs/InvalidateNvBlock, queue-length=1
          operation=NvMService_AC3_SRBS_Defs/ReadBlock, queue-length=1
          operation=NvMService_AC3_SRBS_Defs/RestoreBlockDefaults, queue-length=1
          operation=NvMService_AC3_SRBS_Defs/SetRamBlockStatus, queue-length=1
          operation=NvMService_AC3_SRBS_Defs/WriteBlock, queue-length=1
      PSProxy_Rte_NvmBlock_SysFricLrng_FricNonLrngData: provided-interface=NvMService_AC3_SRBS_Defs
        provided-com-specs:
          operation=NvMService_AC3_SRBS_Defs/EraseBlock, queue-length=1
          operation=NvMService_AC3_SRBS_Defs/GetErrorStatus, queue-length=1
          operation=NvMService_AC3_SRBS_Defs/InvalidateNvBlock, queue-length=1
          operation=NvMService_AC3_SRBS_Defs/ReadBlock, queue-length=1
          operation=NvMService_AC3_SRBS_Defs/RestoreBlockDefaults, queue-length=1
          operation=NvMService_AC3_SRBS_Defs/SetRamBlockStatus, queue-length=1
          operation=NvMService_AC3_SRBS_Defs/WriteBlock, queue-length=1
      PSProxy_Rte_NvmBlock_SysFricLrng_FricLrngData: provided-interface=NvMService_AC3_SRBS_Defs
        provided-com-specs:
          operation=NvMService_AC3_SRBS_Defs/EraseBlock, queue-length=1
          operation=NvMService_AC3_SRBS_Defs/GetErrorStatus, queue-length=1
          operation=NvMService_AC3_SRBS_Defs/InvalidateNvBlock, queue-length=1
          operation=NvMService_AC3_SRBS_Defs/ReadBlock, queue-length=1
          operation=NvMService_AC3_SRBS_Defs/RestoreBlockDefaults, queue-length=1
          operation=NvMService_AC3_SRBS_Defs/SetRamBlockStatus, queue-length=1
          operation=NvMService_AC3_SRBS_Defs/WriteBlock, queue-length=1
      PSProxy_DemPrimaryDataBlock0: provided-interface=NvMService_AC3_SRBS_Defs
        provided-com-specs:
          operation=NvMService_AC3_SRBS_Defs/EraseBlock, queue-length=1
          operation=NvMService_AC3_SRBS_Defs/GetErrorStatus, queue-length=1
          operation=NvMService_AC3_SRBS_Defs/InvalidateNvBlock, queue-length=1
          operation=NvMService_AC3_SRBS_Defs/ReadBlock, queue-length=1
          operation=NvMService_AC3_SRBS_Defs/RestoreBlockDefaults, queue-length=1
          operation=NvMService_AC3_SRBS_Defs/SetRamBlockStatus, queue-length=1
          operation=NvMService_AC3_SRBS_Defs/WriteBlock, queue-length=1
      PSProxy_DemPrimaryDataBlock1: provided-interface=NvMService_AC3_SRBS_Defs
        provided-com-specs:
          operation=NvMService_AC3_SRBS_Defs/EraseBlock, queue-length=1
          operation=NvMService_AC3_SRBS_Defs/GetErrorStatus, queue-length=1
          operation=NvMService_AC3_SRBS_Defs/InvalidateNvBlock, queue-length=1
          operation=NvMService_AC3_SRBS_Defs/ReadBlock, queue-length=1
          operation=NvMService_AC3_SRBS_Defs/RestoreBlockDefaults, queue-length=1
          operation=NvMService_AC3_SRBS_Defs/SetRamBlockStatus, queue-length=1
          operation=NvMService_AC3_SRBS_Defs/WriteBlock, queue-length=1
      PSProxy_DemPrimaryDataBlock2: provided-interface=NvMService_AC3_SRBS_Defs
        provided-com-specs:
          operation=NvMService_AC3_SRBS_Defs/EraseBlock, queue-length=1
          operation=NvMService_AC3_SRBS_Defs/GetErrorStatus, queue-length=1
          operation=NvMService_AC3_SRBS_Defs/InvalidateNvBlock, queue-length=1
          operation=NvMService_AC3_SRBS_Defs/ReadBlock, queue-length=1
          operation=NvMService_AC3_SRBS_Defs/RestoreBlockDefaults, queue-length=1
          operation=NvMService_AC3_SRBS_Defs/SetRamBlockStatus, queue-length=1
          operation=NvMService_AC3_SRBS_Defs/WriteBlock, queue-length=1
      PSProxy_DemPrimaryDataBlock3: provided-interface=NvMService_AC3_SRBS_Defs
        provided-com-specs:
          operation=NvMService_AC3_SRBS_Defs/EraseBlock, queue-length=1
          operation=NvMService_AC3_SRBS_Defs/GetErrorStatus, queue-length=1
          operation=NvMService_AC3_SRBS_Defs/InvalidateNvBlock, queue-length=1
          operation=NvMService_AC3_SRBS_Defs/ReadBlock, queue-length=1
          operation=NvMService_AC3_SRBS_Defs/RestoreBlockDefaults, queue-length=1
          operation=NvMService_AC3_SRBS_Defs/SetRamBlockStatus, queue-length=1
          operation=NvMService_AC3_SRBS_Defs/WriteBlock, queue-length=1
      PSProxy_DemPrimaryDataBlock4: provided-interface=NvMService_AC3_SRBS_Defs
        provided-com-specs:
          operation=NvMService_AC3_SRBS_Defs/EraseBlock, queue-length=1
          operation=NvMService_AC3_SRBS_Defs/GetErrorStatus, queue-length=1
          operation=NvMService_AC3_SRBS_Defs/InvalidateNvBlock, queue-length=1
          operation=NvMService_AC3_SRBS_Defs/ReadBlock, queue-length=1
          operation=NvMService_AC3_SRBS_Defs/RestoreBlockDefaults, queue-length=1
          operation=NvMService_AC3_SRBS_Defs/SetRamBlockStatus, queue-length=1
          operation=NvMService_AC3_SRBS_Defs/WriteBlock, queue-length=1
      PSProxy_DemPrimaryDataBlock5: provided-interface=NvMService_AC3_SRBS_Defs
        provided-com-specs:
          operation=NvMService_AC3_SRBS_Defs/EraseBlock, queue-length=1
          operation=NvMService_AC3_SRBS_Defs/GetErrorStatus, queue-length=1
          operation=NvMService_AC3_SRBS_Defs/InvalidateNvBlock, queue-length=1
          operation=NvMService_AC3_SRBS_Defs/ReadBlock, queue-length=1
          operation=NvMService_AC3_SRBS_Defs/RestoreBlockDefaults, queue-length=1
          operation=NvMService_AC3_SRBS_Defs/SetRamBlockStatus, queue-length=1
          operation=NvMService_AC3_SRBS_Defs/WriteBlock, queue-length=1
      PSProxy_DemPrimaryDataBlock6: provided-interface=NvMService_AC3_SRBS_Defs
        provided-com-specs:
          operation=NvMService_AC3_SRBS_Defs/EraseBlock, queue-length=1
          operation=NvMService_AC3_SRBS_Defs/GetErrorStatus, queue-length=1
          operation=NvMService_AC3_SRBS_Defs/InvalidateNvBlock, queue-length=1
          operation=NvMService_AC3_SRBS_Defs/ReadBlock, queue-length=1
          operation=NvMService_AC3_SRBS_Defs/RestoreBlockDefaults, queue-length=1
          operation=NvMService_AC3_SRBS_Defs/SetRamBlockStatus, queue-length=1
          operation=NvMService_AC3_SRBS_Defs/WriteBlock, queue-length=1
      PSProxy_DemPrimaryDataBlock7: provided-interface=NvMService_AC3_SRBS_Defs
        provided-com-specs:
          operation=NvMService_AC3_SRBS_Defs/EraseBlock, queue-length=1
          operation=NvMService_AC3_SRBS_Defs/GetErrorStatus, queue-length=1
          operation=NvMService_AC3_SRBS_Defs/InvalidateNvBlock, queue-length=1
          operation=NvMService_AC3_SRBS_Defs/ReadBlock, queue-length=1
          operation=NvMService_AC3_SRBS_Defs/RestoreBlockDefaults, queue-length=1
          operation=NvMService_AC3_SRBS_Defs/SetRamBlockStatus, queue-length=1
          operation=NvMService_AC3_SRBS_Defs/WriteBlock, queue-length=1
      PSProxy_DemPrimaryDataBlock8: provided-interface=NvMService_AC3_SRBS_Defs
        provided-com-specs:
          operation=NvMService_AC3_SRBS_Defs/EraseBlock, queue-length=1
          operation=NvMService_AC3_SRBS_Defs/GetErrorStatus, queue-length=1
          operation=NvMService_AC3_SRBS_Defs/InvalidateNvBlock, queue-length=1
          operation=NvMService_AC3_SRBS_Defs/ReadBlock, queue-length=1
          operation=NvMService_AC3_SRBS_Defs/RestoreBlockDefaults, queue-length=1
          operation=NvMService_AC3_SRBS_Defs/SetRamBlockStatus, queue-length=1
          operation=NvMService_AC3_SRBS_Defs/WriteBlock, queue-length=1
      PSProxy_DemPrimaryDataBlock9: provided-interface=NvMService_AC3_SRBS_Defs
        provided-com-specs:
          operation=NvMService_AC3_SRBS_Defs/EraseBlock, queue-length=1
          operation=NvMService_AC3_SRBS_Defs/GetErrorStatus, queue-length=1
          operation=NvMService_AC3_SRBS_Defs/InvalidateNvBlock, queue-length=1
          operation=NvMService_AC3_SRBS_Defs/ReadBlock, queue-length=1
          operation=NvMService_AC3_SRBS_Defs/RestoreBlockDefaults, queue-length=1
          operation=NvMService_AC3_SRBS_Defs/SetRamBlockStatus, queue-length=1
          operation=NvMService_AC3_SRBS_Defs/WriteBlock, queue-length=1
      PSProxy_DemPrimaryDataBlock10: provided-interface=NvMService_AC3_SRBS_Defs
        provided-com-specs:
          operation=NvMService_AC3_SRBS_Defs/EraseBlock, queue-length=1
          operation=NvMService_AC3_SRBS_Defs/GetErrorStatus, queue-length=1
          operation=NvMService_AC3_SRBS_Defs/InvalidateNvBlock, queue-length=1
          operation=NvMService_AC3_SRBS_Defs/ReadBlock, queue-length=1
          operation=NvMService_AC3_SRBS_Defs/RestoreBlockDefaults, queue-length=1
          operation=NvMService_AC3_SRBS_Defs/SetRamBlockStatus, queue-length=1
          operation=NvMService_AC3_SRBS_Defs/WriteBlock, queue-length=1
      PSProxy_DemPrimaryDataBlock11: provided-interface=NvMService_AC3_SRBS_Defs
        provided-com-specs:
          operation=NvMService_AC3_SRBS_Defs/EraseBlock, queue-length=1
          operation=NvMService_AC3_SRBS_Defs/GetErrorStatus, queue-length=1
          operation=NvMService_AC3_SRBS_Defs/InvalidateNvBlock, queue-length=1
          operation=NvMService_AC3_SRBS_Defs/ReadBlock, queue-length=1
          operation=NvMService_AC3_SRBS_Defs/RestoreBlockDefaults, queue-length=1
          operation=NvMService_AC3_SRBS_Defs/SetRamBlockStatus, queue-length=1
          operation=NvMService_AC3_SRBS_Defs/WriteBlock, queue-length=1
      PSProxy_DemPrimaryDataBlock12: provided-interface=NvMService_AC3_SRBS_Defs
        provided-com-specs:
          operation=NvMService_AC3_SRBS_Defs/EraseBlock, queue-length=1
          operation=NvMService_AC3_SRBS_Defs/GetErrorStatus, queue-length=1
          operation=NvMService_AC3_SRBS_Defs/InvalidateNvBlock, queue-length=1
          operation=NvMService_AC3_SRBS_Defs/ReadBlock, queue-length=1
          operation=NvMService_AC3_SRBS_Defs/RestoreBlockDefaults, queue-length=1
          operation=NvMService_AC3_SRBS_Defs/SetRamBlockStatus, queue-length=1
          operation=NvMService_AC3_SRBS_Defs/WriteBlock, queue-length=1
      PSProxy_DemPrimaryDataBlock13: provided-interface=NvMService_AC3_SRBS_Defs
        provided-com-specs:
          operation=NvMService_AC3_SRBS_Defs/EraseBlock, queue-length=1
          operation=NvMService_AC3_SRBS_Defs/GetErrorStatus, queue-length=1
          operation=NvMService_AC3_SRBS_Defs/InvalidateNvBlock, queue-length=1
          operation=NvMService_AC3_SRBS_Defs/ReadBlock, queue-length=1
          operation=NvMService_AC3_SRBS_Defs/RestoreBlockDefaults, queue-length=1
          operation=NvMService_AC3_SRBS_Defs/SetRamBlockStatus, queue-length=1
          operation=NvMService_AC3_SRBS_Defs/WriteBlock, queue-length=1
      PSProxy_DemPrimaryDataBlock14: provided-interface=NvMService_AC3_SRBS_Defs
        provided-com-specs:
          operation=NvMService_AC3_SRBS_Defs/EraseBlock, queue-length=1
          operation=NvMService_AC3_SRBS_Defs/GetErrorStatus, queue-length=1
          operation=NvMService_AC3_SRBS_Defs/InvalidateNvBlock, queue-length=1
          operation=NvMService_AC3_SRBS_Defs/ReadBlock, queue-length=1
          operation=NvMService_AC3_SRBS_Defs/RestoreBlockDefaults, queue-length=1
          operation=NvMService_AC3_SRBS_Defs/SetRamBlockStatus, queue-length=1
          operation=NvMService_AC3_SRBS_Defs/WriteBlock, queue-length=1
      PSProxy_DemPrimaryDataBlock15: provided-interface=NvMService_AC3_SRBS_Defs
        provided-com-specs:
          operation=NvMService_AC3_SRBS_Defs/EraseBlock, queue-length=1
          operation=NvMService_AC3_SRBS_Defs/GetErrorStatus, queue-length=1
          operation=NvMService_AC3_SRBS_Defs/InvalidateNvBlock, queue-length=1
          operation=NvMService_AC3_SRBS_Defs/ReadBlock, queue-length=1
          operation=NvMService_AC3_SRBS_Defs/RestoreBlockDefaults, queue-length=1
          operation=NvMService_AC3_SRBS_Defs/SetRamBlockStatus, queue-length=1
          operation=NvMService_AC3_SRBS_Defs/WriteBlock, queue-length=1
      PSProxy_DemPrimaryDataBlock16: provided-interface=NvMService_AC3_SRBS_Defs
        provided-com-specs:
          operation=NvMService_AC3_SRBS_Defs/EraseBlock, queue-length=1
          operation=NvMService_AC3_SRBS_Defs/GetErrorStatus, queue-length=1
          operation=NvMService_AC3_SRBS_Defs/InvalidateNvBlock, queue-length=1
          operation=NvMService_AC3_SRBS_Defs/ReadBlock, queue-length=1
          operation=NvMService_AC3_SRBS_Defs/RestoreBlockDefaults, queue-length=1
          operation=NvMService_AC3_SRBS_Defs/SetRamBlockStatus, queue-length=1
          operation=NvMService_AC3_SRBS_Defs/WriteBlock, queue-length=1
      PSProxy_DemPrimaryDataBlock17: provided-interface=NvMService_AC3_SRBS_Defs
        provided-com-specs:
          operation=NvMService_AC3_SRBS_Defs/EraseBlock, queue-length=1
          operation=NvMService_AC3_SRBS_Defs/GetErrorStatus, queue-length=1
          operation=NvMService_AC3_SRBS_Defs/InvalidateNvBlock, queue-length=1
          operation=NvMService_AC3_SRBS_Defs/ReadBlock, queue-length=1
          operation=NvMService_AC3_SRBS_Defs/RestoreBlockDefaults, queue-length=1
          operation=NvMService_AC3_SRBS_Defs/SetRamBlockStatus, queue-length=1
          operation=NvMService_AC3_SRBS_Defs/WriteBlock, queue-length=1
      PSProxy_DemPrimaryDataBlock18: provided-interface=NvMService_AC3_SRBS_Defs
        provided-com-specs:
          operation=NvMService_AC3_SRBS_Defs/EraseBlock, queue-length=1
          operation=NvMService_AC3_SRBS_Defs/GetErrorStatus, queue-length=1
          operation=NvMService_AC3_SRBS_Defs/InvalidateNvBlock, queue-length=1
          operation=NvMService_AC3_SRBS_Defs/ReadBlock, queue-length=1
          operation=NvMService_AC3_SRBS_Defs/RestoreBlockDefaults, queue-length=1
          operation=NvMService_AC3_SRBS_Defs/SetRamBlockStatus, queue-length=1
          operation=NvMService_AC3_SRBS_Defs/WriteBlock, queue-length=1
      PSProxy_DemPrimaryDataBlock19: provided-interface=NvMService_AC3_SRBS_Defs
        provided-com-specs:
          operation=NvMService_AC3_SRBS_Defs/EraseBlock, queue-length=1
          operation=NvMService_AC3_SRBS_Defs/GetErrorStatus, queue-length=1
          operation=NvMService_AC3_SRBS_Defs/InvalidateNvBlock, queue-length=1
          operation=NvMService_AC3_SRBS_Defs/ReadBlock, queue-length=1
          operation=NvMService_AC3_SRBS_Defs/RestoreBlockDefaults, queue-length=1
          operation=NvMService_AC3_SRBS_Defs/SetRamBlockStatus, queue-length=1
          operation=NvMService_AC3_SRBS_Defs/WriteBlock, queue-length=1
      PSProxy_DemPrimaryDataBlock20: provided-interface=NvMService_AC3_SRBS_Defs
        provided-com-specs:
          operation=NvMService_AC3_SRBS_Defs/EraseBlock, queue-length=1
          operation=NvMService_AC3_SRBS_Defs/GetErrorStatus, queue-length=1
          operation=NvMService_AC3_SRBS_Defs/InvalidateNvBlock, queue-length=1
          operation=NvMService_AC3_SRBS_Defs/ReadBlock, queue-length=1
          operation=NvMService_AC3_SRBS_Defs/RestoreBlockDefaults, queue-length=1
          operation=NvMService_AC3_SRBS_Defs/SetRamBlockStatus, queue-length=1
          operation=NvMService_AC3_SRBS_Defs/WriteBlock, queue-length=1
      PSProxy_DemPrimaryDataBlock21: provided-interface=NvMService_AC3_SRBS_Defs
        provided-com-specs:
          operation=NvMService_AC3_SRBS_Defs/EraseBlock, queue-length=1
          operation=NvMService_AC3_SRBS_Defs/GetErrorStatus, queue-length=1
          operation=NvMService_AC3_SRBS_Defs/InvalidateNvBlock, queue-length=1
          operation=NvMService_AC3_SRBS_Defs/ReadBlock, queue-length=1
          operation=NvMService_AC3_SRBS_Defs/RestoreBlockDefaults, queue-length=1
          operation=NvMService_AC3_SRBS_Defs/SetRamBlockStatus, queue-length=1
          operation=NvMService_AC3_SRBS_Defs/WriteBlock, queue-length=1
      PSProxy_DemPrimaryDataBlock22: provided-interface=NvMService_AC3_SRBS_Defs
        provided-com-specs:
          operation=NvMService_AC3_SRBS_Defs/EraseBlock, queue-length=1
          operation=NvMService_AC3_SRBS_Defs/GetErrorStatus, queue-length=1
          operation=NvMService_AC3_SRBS_Defs/InvalidateNvBlock, queue-length=1
          operation=NvMService_AC3_SRBS_Defs/ReadBlock, queue-length=1
          operation=NvMService_AC3_SRBS_Defs/RestoreBlockDefaults, queue-length=1
          operation=NvMService_AC3_SRBS_Defs/SetRamBlockStatus, queue-length=1
          operation=NvMService_AC3_SRBS_Defs/WriteBlock, queue-length=1
      PSProxy_DemPrimaryDataBlock23: provided-interface=NvMService_AC3_SRBS_Defs
        provided-com-specs:
          operation=NvMService_AC3_SRBS_Defs/EraseBlock, queue-length=1
          operation=NvMService_AC3_SRBS_Defs/GetErrorStatus, queue-length=1
          operation=NvMService_AC3_SRBS_Defs/InvalidateNvBlock, queue-length=1
          operation=NvMService_AC3_SRBS_Defs/ReadBlock, queue-length=1
          operation=NvMService_AC3_SRBS_Defs/RestoreBlockDefaults, queue-length=1
          operation=NvMService_AC3_SRBS_Defs/SetRamBlockStatus, queue-length=1
          operation=NvMService_AC3_SRBS_Defs/WriteBlock, queue-length=1
      PSProxy_DemPrimaryDataBlock24: provided-interface=NvMService_AC3_SRBS_Defs
        provided-com-specs:
          operation=NvMService_AC3_SRBS_Defs/EraseBlock, queue-length=1
          operation=NvMService_AC3_SRBS_Defs/GetErrorStatus, queue-length=1
          operation=NvMService_AC3_SRBS_Defs/InvalidateNvBlock, queue-length=1
          operation=NvMService_AC3_SRBS_Defs/ReadBlock, queue-length=1
          operation=NvMService_AC3_SRBS_Defs/RestoreBlockDefaults, queue-length=1
          operation=NvMService_AC3_SRBS_Defs/SetRamBlockStatus, queue-length=1
          operation=NvMService_AC3_SRBS_Defs/WriteBlock, queue-length=1
      PSProxy_DemPrimaryDataBlock25: provided-interface=NvMService_AC3_SRBS_Defs
        provided-com-specs:
          operation=NvMService_AC3_SRBS_Defs/EraseBlock, queue-length=1
          operation=NvMService_AC3_SRBS_Defs/GetErrorStatus, queue-length=1
          operation=NvMService_AC3_SRBS_Defs/InvalidateNvBlock, queue-length=1
          operation=NvMService_AC3_SRBS_Defs/ReadBlock, queue-length=1
          operation=NvMService_AC3_SRBS_Defs/RestoreBlockDefaults, queue-length=1
          operation=NvMService_AC3_SRBS_Defs/SetRamBlockStatus, queue-length=1
          operation=NvMService_AC3_SRBS_Defs/WriteBlock, queue-length=1
      PSProxy_DemPrimaryDataBlock26: provided-interface=NvMService_AC3_SRBS_Defs
        provided-com-specs:
          operation=NvMService_AC3_SRBS_Defs/EraseBlock, queue-length=1
          operation=NvMService_AC3_SRBS_Defs/GetErrorStatus, queue-length=1
          operation=NvMService_AC3_SRBS_Defs/InvalidateNvBlock, queue-length=1
          operation=NvMService_AC3_SRBS_Defs/ReadBlock, queue-length=1
          operation=NvMService_AC3_SRBS_Defs/RestoreBlockDefaults, queue-length=1
          operation=NvMService_AC3_SRBS_Defs/SetRamBlockStatus, queue-length=1
          operation=NvMService_AC3_SRBS_Defs/WriteBlock, queue-length=1
      PSProxy_DemPrimaryDataBlock27: provided-interface=NvMService_AC3_SRBS_Defs
        provided-com-specs:
          operation=NvMService_AC3_SRBS_Defs/EraseBlock, queue-length=1
          operation=NvMService_AC3_SRBS_Defs/GetErrorStatus, queue-length=1
          operation=NvMService_AC3_SRBS_Defs/InvalidateNvBlock, queue-length=1
          operation=NvMService_AC3_SRBS_Defs/ReadBlock, queue-length=1
          operation=NvMService_AC3_SRBS_Defs/RestoreBlockDefaults, queue-length=1
          operation=NvMService_AC3_SRBS_Defs/SetRamBlockStatus, queue-length=1
          operation=NvMService_AC3_SRBS_Defs/WriteBlock, queue-length=1
      PSProxy_DemPrimaryDataBlock28: provided-interface=NvMService_AC3_SRBS_Defs
        provided-com-specs:
          operation=NvMService_AC3_SRBS_Defs/EraseBlock, queue-length=1
          operation=NvMService_AC3_SRBS_Defs/GetErrorStatus, queue-length=1
          operation=NvMService_AC3_SRBS_Defs/InvalidateNvBlock, queue-length=1
          operation=NvMService_AC3_SRBS_Defs/ReadBlock, queue-length=1
          operation=NvMService_AC3_SRBS_Defs/RestoreBlockDefaults, queue-length=1
          operation=NvMService_AC3_SRBS_Defs/SetRamBlockStatus, queue-length=1
          operation=NvMService_AC3_SRBS_Defs/WriteBlock, queue-length=1
      PSProxy_DemPrimaryDataBlock29: provided-interface=NvMService_AC3_SRBS_Defs
        provided-com-specs:
          operation=NvMService_AC3_SRBS_Defs/EraseBlock, queue-length=1
          operation=NvMService_AC3_SRBS_Defs/GetErrorStatus, queue-length=1
          operation=NvMService_AC3_SRBS_Defs/InvalidateNvBlock, queue-length=1
          operation=NvMService_AC3_SRBS_Defs/ReadBlock, queue-length=1
          operation=NvMService_AC3_SRBS_Defs/RestoreBlockDefaults, queue-length=1
          operation=NvMService_AC3_SRBS_Defs/SetRamBlockStatus, queue-length=1
          operation=NvMService_AC3_SRBS_Defs/WriteBlock, queue-length=1
      PSProxy_DemPrimaryDataBlock30: provided-interface=NvMService_AC3_SRBS_Defs
        provided-com-specs:
          operation=NvMService_AC3_SRBS_Defs/EraseBlock, queue-length=1
          operation=NvMService_AC3_SRBS_Defs/GetErrorStatus, queue-length=1
          operation=NvMService_AC3_SRBS_Defs/InvalidateNvBlock, queue-length=1
          operation=NvMService_AC3_SRBS_Defs/ReadBlock, queue-length=1
          operation=NvMService_AC3_SRBS_Defs/RestoreBlockDefaults, queue-length=1
          operation=NvMService_AC3_SRBS_Defs/SetRamBlockStatus, queue-length=1
          operation=NvMService_AC3_SRBS_Defs/WriteBlock, queue-length=1
      PSProxy_DemPrimaryDataBlock31: provided-interface=NvMService_AC3_SRBS_Defs
        provided-com-specs:
          operation=NvMService_AC3_SRBS_Defs/EraseBlock, queue-length=1
          operation=NvMService_AC3_SRBS_Defs/GetErrorStatus, queue-length=1
          operation=NvMService_AC3_SRBS_Defs/InvalidateNvBlock, queue-length=1
          operation=NvMService_AC3_SRBS_Defs/ReadBlock, queue-length=1
          operation=NvMService_AC3_SRBS_Defs/RestoreBlockDefaults, queue-length=1
          operation=NvMService_AC3_SRBS_Defs/SetRamBlockStatus, queue-length=1
          operation=NvMService_AC3_SRBS_Defs/WriteBlock, queue-length=1
      PSProxy_DemPrimaryDataBlock32: provided-interface=NvMService_AC3_SRBS_Defs
        provided-com-specs:
          operation=NvMService_AC3_SRBS_Defs/EraseBlock, queue-length=1
          operation=NvMService_AC3_SRBS_Defs/GetErrorStatus, queue-length=1
          operation=NvMService_AC3_SRBS_Defs/InvalidateNvBlock, queue-length=1
          operation=NvMService_AC3_SRBS_Defs/ReadBlock, queue-length=1
          operation=NvMService_AC3_SRBS_Defs/RestoreBlockDefaults, queue-length=1
          operation=NvMService_AC3_SRBS_Defs/SetRamBlockStatus, queue-length=1
          operation=NvMService_AC3_SRBS_Defs/WriteBlock, queue-length=1
      PSProxy_DemPrimaryDataBlock33: provided-interface=NvMService_AC3_SRBS_Defs
        provided-com-specs:
          operation=NvMService_AC3_SRBS_Defs/EraseBlock, queue-length=1
          operation=NvMService_AC3_SRBS_Defs/GetErrorStatus, queue-length=1
          operation=NvMService_AC3_SRBS_Defs/InvalidateNvBlock, queue-length=1
          operation=NvMService_AC3_SRBS_Defs/ReadBlock, queue-length=1
          operation=NvMService_AC3_SRBS_Defs/RestoreBlockDefaults, queue-length=1
          operation=NvMService_AC3_SRBS_Defs/SetRamBlockStatus, queue-length=1
          operation=NvMService_AC3_SRBS_Defs/WriteBlock, queue-length=1
      PSProxy_DemPrimaryDataBlock34: provided-interface=NvMService_AC3_SRBS_Defs
        provided-com-specs:
          operation=NvMService_AC3_SRBS_Defs/EraseBlock, queue-length=1
          operation=NvMService_AC3_SRBS_Defs/GetErrorStatus, queue-length=1
          operation=NvMService_AC3_SRBS_Defs/InvalidateNvBlock, queue-length=1
          operation=NvMService_AC3_SRBS_Defs/ReadBlock, queue-length=1
          operation=NvMService_AC3_SRBS_Defs/RestoreBlockDefaults, queue-length=1
          operation=NvMService_AC3_SRBS_Defs/SetRamBlockStatus, queue-length=1
          operation=NvMService_AC3_SRBS_Defs/WriteBlock, queue-length=1
      PSProxy_DemPrimaryDataBlock35: provided-interface=NvMService_AC3_SRBS_Defs
        provided-com-specs:
          operation=NvMService_AC3_SRBS_Defs/EraseBlock, queue-length=1
          operation=NvMService_AC3_SRBS_Defs/GetErrorStatus, queue-length=1
          operation=NvMService_AC3_SRBS_Defs/InvalidateNvBlock, queue-length=1
          operation=NvMService_AC3_SRBS_Defs/ReadBlock, queue-length=1
          operation=NvMService_AC3_SRBS_Defs/RestoreBlockDefaults, queue-length=1
          operation=NvMService_AC3_SRBS_Defs/SetRamBlockStatus, queue-length=1
          operation=NvMService_AC3_SRBS_Defs/WriteBlock, queue-length=1
      PSProxy_DemPrimaryDataBlock36: provided-interface=NvMService_AC3_SRBS_Defs
        provided-com-specs:
          operation=NvMService_AC3_SRBS_Defs/EraseBlock, queue-length=1
          operation=NvMService_AC3_SRBS_Defs/GetErrorStatus, queue-length=1
          operation=NvMService_AC3_SRBS_Defs/InvalidateNvBlock, queue-length=1
          operation=NvMService_AC3_SRBS_Defs/ReadBlock, queue-length=1
          operation=NvMService_AC3_SRBS_Defs/RestoreBlockDefaults, queue-length=1
          operation=NvMService_AC3_SRBS_Defs/SetRamBlockStatus, queue-length=1
          operation=NvMService_AC3_SRBS_Defs/WriteBlock, queue-length=1
      PSProxy_DemPrimaryDataBlock37: provided-interface=NvMService_AC3_SRBS_Defs
        provided-com-specs:
          operation=NvMService_AC3_SRBS_Defs/EraseBlock, queue-length=1
          operation=NvMService_AC3_SRBS_Defs/GetErrorStatus, queue-length=1
          operation=NvMService_AC3_SRBS_Defs/InvalidateNvBlock, queue-length=1
          operation=NvMService_AC3_SRBS_Defs/ReadBlock, queue-length=1
          operation=NvMService_AC3_SRBS_Defs/RestoreBlockDefaults, queue-length=1
          operation=NvMService_AC3_SRBS_Defs/SetRamBlockStatus, queue-length=1
          operation=NvMService_AC3_SRBS_Defs/WriteBlock, queue-length=1
      PSProxy_DemPrimaryDataBlock38: provided-interface=NvMService_AC3_SRBS_Defs
        provided-com-specs:
          operation=NvMService_AC3_SRBS_Defs/EraseBlock, queue-length=1
          operation=NvMService_AC3_SRBS_Defs/GetErrorStatus, queue-length=1
          operation=NvMService_AC3_SRBS_Defs/InvalidateNvBlock, queue-length=1
          operation=NvMService_AC3_SRBS_Defs/ReadBlock, queue-length=1
          operation=NvMService_AC3_SRBS_Defs/RestoreBlockDefaults, queue-length=1
          operation=NvMService_AC3_SRBS_Defs/SetRamBlockStatus, queue-length=1
          operation=NvMService_AC3_SRBS_Defs/WriteBlock, queue-length=1
      PSProxy_DemPrimaryDataBlock39: provided-interface=NvMService_AC3_SRBS_Defs
        provided-com-specs:
          operation=NvMService_AC3_SRBS_Defs/EraseBlock, queue-length=1
          operation=NvMService_AC3_SRBS_Defs/GetErrorStatus, queue-length=1
          operation=NvMService_AC3_SRBS_Defs/InvalidateNvBlock, queue-length=1
          operation=NvMService_AC3_SRBS_Defs/ReadBlock, queue-length=1
          operation=NvMService_AC3_SRBS_Defs/RestoreBlockDefaults, queue-length=1
          operation=NvMService_AC3_SRBS_Defs/SetRamBlockStatus, queue-length=1
          operation=NvMService_AC3_SRBS_Defs/WriteBlock, queue-length=1
      PSProxy_Rte_NvmBlock_HwAgSnsrls_StordLstPrm: provided-interface=NvMService_AC3_SRBS_Defs
        provided-com-specs:
          operation=NvMService_AC3_SRBS_Defs/EraseBlock, queue-length=1
          operation=NvMService_AC3_SRBS_Defs/GetErrorStatus, queue-length=1
          operation=NvMService_AC3_SRBS_Defs/InvalidateNvBlock, queue-length=1
          operation=NvMService_AC3_SRBS_Defs/ReadBlock, queue-length=1
          operation=NvMService_AC3_SRBS_Defs/RestoreBlockDefaults, queue-length=1
          operation=NvMService_AC3_SRBS_Defs/SetRamBlockStatus, queue-length=1
          operation=NvMService_AC3_SRBS_Defs/WriteBlock, queue-length=1
      PSProxy_Rte_NvmBlock_CmnMfgSrv_SeedKey: provided-interface=NvMService_AC3_SRBS_Defs
        provided-com-specs:
          operation=NvMService_AC3_SRBS_Defs/EraseBlock, queue-length=1
          operation=NvMService_AC3_SRBS_Defs/GetErrorStatus, queue-length=1
          operation=NvMService_AC3_SRBS_Defs/InvalidateNvBlock, queue-length=1
          operation=NvMService_AC3_SRBS_Defs/ReadBlock, queue-length=1
          operation=NvMService_AC3_SRBS_Defs/RestoreBlockDefaults, queue-length=1
          operation=NvMService_AC3_SRBS_Defs/SetRamBlockStatus, queue-length=1
          operation=NvMService_AC3_SRBS_Defs/WriteBlock, queue-length=1
      PSProxy_CurrMeasMotEol_Deprecated: provided-interface=NvMService_AC3_SRBS
        provided-com-specs:
          operation=NvMService_AC3_SRBS/EraseBlock, queue-length=1
          operation=NvMService_AC3_SRBS/GetErrorStatus, queue-length=1
          operation=NvMService_AC3_SRBS/InvalidateNvBlock, queue-length=1
          operation=NvMService_AC3_SRBS/ReadBlock, queue-length=1
          operation=NvMService_AC3_SRBS/SetRamBlockStatus, queue-length=1
          operation=NvMService_AC3_SRBS/WriteBlock, queue-length=1
      PSProxy_PolarityCfgSaved: provided-interface=NvMService_AC3_SRBS
        provided-com-specs:
          operation=NvMService_AC3_SRBS/EraseBlock, queue-length=1
          operation=NvMService_AC3_SRBS/GetErrorStatus, queue-length=1
          operation=NvMService_AC3_SRBS/InvalidateNvBlock, queue-length=1
          operation=NvMService_AC3_SRBS/ReadBlock, queue-length=1
          operation=NvMService_AC3_SRBS/SetRamBlockStatus, queue-length=1
          operation=NvMService_AC3_SRBS/WriteBlock, queue-length=1
      PSProxy_MotPrmNom: provided-interface=NvMService_AC3_SRBS
        provided-com-specs:
          operation=NvMService_AC3_SRBS/EraseBlock, queue-length=1
          operation=NvMService_AC3_SRBS/GetErrorStatus, queue-length=1
          operation=NvMService_AC3_SRBS/InvalidateNvBlock, queue-length=1
          operation=NvMService_AC3_SRBS/ReadBlock, queue-length=1
          operation=NvMService_AC3_SRBS/SetRamBlockStatus, queue-length=1
          operation=NvMService_AC3_SRBS/WriteBlock, queue-length=1
      PSProxy_Rte_NvmBlock_NvMProxy_ShtdwnClsChk: provided-interface=NvMService_AC3_SRBS
        provided-com-specs:
          operation=NvMService_AC3_SRBS/EraseBlock, queue-length=1
          operation=NvMService_AC3_SRBS/GetErrorStatus, queue-length=1
          operation=NvMService_AC3_SRBS/InvalidateNvBlock, queue-length=1
          operation=NvMService_AC3_SRBS/ReadBlock, queue-length=1
          operation=NvMService_AC3_SRBS/SetRamBlockStatus, queue-length=1
          operation=NvMService_AC3_SRBS/WriteBlock, queue-length=1
      PSProxy_Rte_NvmBlock_DiagcMgr_DiagcMgrNtcFltAry: provided-interface=NvMService_AC3_SRBS
        provided-com-specs:
          operation=NvMService_AC3_SRBS/EraseBlock, queue-length=1
          operation=NvMService_AC3_SRBS/GetErrorStatus, queue-length=1
          operation=NvMService_AC3_SRBS/InvalidateNvBlock, queue-length=1
          operation=NvMService_AC3_SRBS/ReadBlock, queue-length=1
          operation=NvMService_AC3_SRBS/SetRamBlockStatus, queue-length=1
          operation=NvMService_AC3_SRBS/WriteBlock, queue-length=1
      PSProxy_Rte_NvmBlock_CmnMfgSrv_MfgTmpBuf4: provided-interface=NvMService_AC3_SRBS
        provided-com-specs:
          operation=NvMService_AC3_SRBS/EraseBlock, queue-length=1
          operation=NvMService_AC3_SRBS/GetErrorStatus, queue-length=1
          operation=NvMService_AC3_SRBS/InvalidateNvBlock, queue-length=1
          operation=NvMService_AC3_SRBS/ReadBlock, queue-length=1
          operation=NvMService_AC3_SRBS/SetRamBlockStatus, queue-length=1
          operation=NvMService_AC3_SRBS/WriteBlock, queue-length=1
      PSProxy_Rte_NvmBlock_CmnMfgSrv_EpsSysSerlNr: provided-interface=NvMService_AC3_SRBS
        provided-com-specs:
          operation=NvMService_AC3_SRBS/EraseBlock, queue-length=1
          operation=NvMService_AC3_SRBS/GetErrorStatus, queue-length=1
          operation=NvMService_AC3_SRBS/InvalidateNvBlock, queue-length=1
          operation=NvMService_AC3_SRBS/ReadBlock, queue-length=1
          operation=NvMService_AC3_SRBS/SetRamBlockStatus, queue-length=1
          operation=NvMService_AC3_SRBS/WriteBlock, queue-length=1
      PSProxy_Rte_NvmBlock_CmnMfgSrv_MfgTmpBuf3: provided-interface=NvMService_AC3_SRBS
        provided-com-specs:
          operation=NvMService_AC3_SRBS/EraseBlock, queue-length=1
          operation=NvMService_AC3_SRBS/GetErrorStatus, queue-length=1
          operation=NvMService_AC3_SRBS/InvalidateNvBlock, queue-length=1
          operation=NvMService_AC3_SRBS/ReadBlock, queue-length=1
          operation=NvMService_AC3_SRBS/SetRamBlockStatus, queue-length=1
          operation=NvMService_AC3_SRBS/WriteBlock, queue-length=1
      PSProxy_Rte_NvmBlock_CmnMfgSrv_DiRestore: provided-interface=NvMService_AC3_SRBS
        provided-com-specs:
          operation=NvMService_AC3_SRBS/EraseBlock, queue-length=1
          operation=NvMService_AC3_SRBS/GetErrorStatus, queue-length=1
          operation=NvMService_AC3_SRBS/InvalidateNvBlock, queue-length=1
          operation=NvMService_AC3_SRBS/ReadBlock, queue-length=1
          operation=NvMService_AC3_SRBS/SetRamBlockStatus, queue-length=1
          operation=NvMService_AC3_SRBS/WriteBlock, queue-length=1
      PSProxy_Rte_NvmBlock_CmnMfgSrv_MfgTmpBuf2: provided-interface=NvMService_AC3_SRBS
        provided-com-specs:
          operation=NvMService_AC3_SRBS/EraseBlock, queue-length=1
          operation=NvMService_AC3_SRBS/GetErrorStatus, queue-length=1
          operation=NvMService_AC3_SRBS/InvalidateNvBlock, queue-length=1
          operation=NvMService_AC3_SRBS/ReadBlock, queue-length=1
          operation=NvMService_AC3_SRBS/SetRamBlockStatus, queue-length=1
          operation=NvMService_AC3_SRBS/WriteBlock, queue-length=1
      PSProxy_Rte_NvmBlock_CmnMfgSrv_MfgTmpBuf1: provided-interface=NvMService_AC3_SRBS
        provided-com-specs:
          operation=NvMService_AC3_SRBS/EraseBlock, queue-length=1
          operation=NvMService_AC3_SRBS/GetErrorStatus, queue-length=1
          operation=NvMService_AC3_SRBS/InvalidateNvBlock, queue-length=1
          operation=NvMService_AC3_SRBS/ReadBlock, queue-length=1
          operation=NvMService_AC3_SRBS/SetRamBlockStatus, queue-length=1
          operation=NvMService_AC3_SRBS/WriteBlock, queue-length=1
      PSProxy_Rte_NvmBlock_CmnMfgSrv_CcaHwPartNr: provided-interface=NvMService_AC3_SRBS
        provided-com-specs:
          operation=NvMService_AC3_SRBS/EraseBlock, queue-length=1
          operation=NvMService_AC3_SRBS/GetErrorStatus, queue-length=1
          operation=NvMService_AC3_SRBS/InvalidateNvBlock, queue-length=1
          operation=NvMService_AC3_SRBS/ReadBlock, queue-length=1
          operation=NvMService_AC3_SRBS/SetRamBlockStatus, queue-length=1
          operation=NvMService_AC3_SRBS/WriteBlock, queue-length=1
      PSProxy_Rte_NvmBlock_CmnMfgSrv_MfgTmpBuf0: provided-interface=NvMService_AC3_SRBS
        provided-com-specs:
          operation=NvMService_AC3_SRBS/EraseBlock, queue-length=1
          operation=NvMService_AC3_SRBS/GetErrorStatus, queue-length=1
          operation=NvMService_AC3_SRBS/InvalidateNvBlock, queue-length=1
          operation=NvMService_AC3_SRBS/ReadBlock, queue-length=1
          operation=NvMService_AC3_SRBS/SetRamBlockStatus, queue-length=1
          operation=NvMService_AC3_SRBS/WriteBlock, queue-length=1
      PSProxy_Rte_NvmBlock_CmnMfgSrv_CcaSerlNr: provided-interface=NvMService_AC3_SRBS
        provided-com-specs:
          operation=NvMService_AC3_SRBS/EraseBlock, queue-length=1
          operation=NvMService_AC3_SRBS/GetErrorStatus, queue-length=1
          operation=NvMService_AC3_SRBS/InvalidateNvBlock, queue-length=1
          operation=NvMService_AC3_SRBS/ReadBlock, queue-length=1
          operation=NvMService_AC3_SRBS/SetRamBlockStatus, queue-length=1
          operation=NvMService_AC3_SRBS/WriteBlock, queue-length=1
      PSProxy_Rte_NvmBlock_DutyCycThermProtn_FilStVal: provided-interface=NvMService_AC3_SRBS
        provided-com-specs:
          operation=NvMService_AC3_SRBS/EraseBlock, queue-length=1
          operation=NvMService_AC3_SRBS/GetErrorStatus, queue-length=1
          operation=NvMService_AC3_SRBS/InvalidateNvBlock, queue-length=1
          operation=NvMService_AC3_SRBS/ReadBlock, queue-length=1
          operation=NvMService_AC3_SRBS/SetRamBlockStatus, queue-length=1
          operation=NvMService_AC3_SRBS/WriteBlock, queue-length=1
      PSProxy_Rte_NvmBlock_MotTqCmdSca_MotTqScaFac: provided-interface=NvMService_AC3_SRBS
        provided-com-specs:
          operation=NvMService_AC3_SRBS/EraseBlock, queue-length=1
          operation=NvMService_AC3_SRBS/GetErrorStatus, queue-length=1
          operation=NvMService_AC3_SRBS/InvalidateNvBlock, queue-length=1
          operation=NvMService_AC3_SRBS/ReadBlock, queue-length=1
          operation=NvMService_AC3_SRBS/SetRamBlockStatus, queue-length=1
          operation=NvMService_AC3_SRBS/WriteBlock, queue-length=1
      PSProxy_Rte_NvmBlock_SnsrOffsLrng_SnsrOffsLrnd: provided-interface=NvMService_AC3_SRBS
        provided-com-specs:
          operation=NvMService_AC3_SRBS/EraseBlock, queue-length=1
          operation=NvMService_AC3_SRBS/GetErrorStatus, queue-length=1
          operation=NvMService_AC3_SRBS/InvalidateNvBlock, queue-length=1
          operation=NvMService_AC3_SRBS/ReadBlock, queue-length=1
          operation=NvMService_AC3_SRBS/SetRamBlockStatus, queue-length=1
          operation=NvMService_AC3_SRBS/WriteBlock, queue-length=1
      PSProxy_Rte_NvmBlock_GmOvrlStMgr_GmLoaIgnCntr: provided-interface=NvMService_AC3_SRBS
        provided-com-specs:
          operation=NvMService_AC3_SRBS/EraseBlock, queue-length=1
          operation=NvMService_AC3_SRBS/GetErrorStatus, queue-length=1
          operation=NvMService_AC3_SRBS/InvalidateNvBlock, queue-length=1
          operation=NvMService_AC3_SRBS/ReadBlock, queue-length=1
          operation=NvMService_AC3_SRBS/SetRamBlockStatus, queue-length=1
          operation=NvMService_AC3_SRBS/WriteBlock, queue-length=1
      PSProxy_Rte_NvmBlock_MotRplCoggCfg_MotRplCoggPrm: provided-interface=NvMService_AC3_SRBS
        provided-com-specs:
          operation=NvMService_AC3_SRBS/EraseBlock, queue-length=1
          operation=NvMService_AC3_SRBS/GetErrorStatus, queue-length=1
          operation=NvMService_AC3_SRBS/InvalidateNvBlock, queue-length=1
          operation=NvMService_AC3_SRBS/ReadBlock, queue-length=1
          operation=NvMService_AC3_SRBS/SetRamBlockStatus, queue-length=1
          operation=NvMService_AC3_SRBS/WriteBlock, queue-length=1
      PSProxy_Rte_NvmBlock_CDD_MotRplCoggCmd_MotCoggCmdY: provided-interface=NvMService_AC3_SRBS
        provided-com-specs:
          operation=NvMService_AC3_SRBS/EraseBlock, queue-length=1
          operation=NvMService_AC3_SRBS/GetErrorStatus, queue-length=1
          operation=NvMService_AC3_SRBS/InvalidateNvBlock, queue-length=1
          operation=NvMService_AC3_SRBS/ReadBlock, queue-length=1
          operation=NvMService_AC3_SRBS/SetRamBlockStatus, queue-length=1
          operation=NvMService_AC3_SRBS/WriteBlock, queue-length=1
      PSProxy_Rte_NvmBlock_StHlthSigStc_SigStcHistDataAry: provided-interface=NvMService_AC3_SRBS
        provided-com-specs:
          operation=NvMService_AC3_SRBS/EraseBlock, queue-length=1
          operation=NvMService_AC3_SRBS/GetErrorStatus, queue-length=1
          operation=NvMService_AC3_SRBS/InvalidateNvBlock, queue-length=1
          operation=NvMService_AC3_SRBS/ReadBlock, queue-length=1
          operation=NvMService_AC3_SRBS/SetRamBlockStatus, queue-length=1
          operation=NvMService_AC3_SRBS/WriteBlock, queue-length=1
      PSProxy_Rte_NvmBlock_HwAgVehCentrTrim_HwAgTrimVal_Deprecated: provided-interface=NvMService_AC3_SRBS
        provided-com-specs:
          operation=NvMService_AC3_SRBS/EraseBlock, queue-length=1
          operation=NvMService_AC3_SRBS/GetErrorStatus, queue-length=1
          operation=NvMService_AC3_SRBS/InvalidateNvBlock, queue-length=1
          operation=NvMService_AC3_SRBS/ReadBlock, queue-length=1
          operation=NvMService_AC3_SRBS/SetRamBlockStatus, queue-length=1
          operation=NvMService_AC3_SRBS/WriteBlock, queue-length=1
      PSProxy_Rte_NvmBlock_WhlImbRejctn_MaxCompPerc_Deprecated: provided-interface=NvMService_AC3_SRBS
        provided-com-specs:
          operation=NvMService_AC3_SRBS/EraseBlock, queue-length=1
          operation=NvMService_AC3_SRBS/GetErrorStatus, queue-length=1
          operation=NvMService_AC3_SRBS/InvalidateNvBlock, queue-length=1
          operation=NvMService_AC3_SRBS/ReadBlock, queue-length=1
          operation=NvMService_AC3_SRBS/SetRamBlockStatus, queue-length=1
          operation=NvMService_AC3_SRBS/WriteBlock, queue-length=1
      PSProxy_Rte_NvmBlock_WhlImbRejctn_ActvCmpBand3_Deprecated: provided-interface=NvMService_AC3_SRBS
        provided-com-specs:
          operation=NvMService_AC3_SRBS/EraseBlock, queue-length=1
          operation=NvMService_AC3_SRBS/GetErrorStatus, queue-length=1
          operation=NvMService_AC3_SRBS/InvalidateNvBlock, queue-length=1
          operation=NvMService_AC3_SRBS/ReadBlock, queue-length=1
          operation=NvMService_AC3_SRBS/SetRamBlockStatus, queue-length=1
          operation=NvMService_AC3_SRBS/WriteBlock, queue-length=1
      PSProxy_Rte_NvmBlock_WhlImbRejctn_ActvCmpBand1_Deprecated: provided-interface=NvMService_AC3_SRBS
        provided-com-specs:
          operation=NvMService_AC3_SRBS/EraseBlock, queue-length=1
          operation=NvMService_AC3_SRBS/GetErrorStatus, queue-length=1
          operation=NvMService_AC3_SRBS/InvalidateNvBlock, queue-length=1
          operation=NvMService_AC3_SRBS/ReadBlock, queue-length=1
          operation=NvMService_AC3_SRBS/SetRamBlockStatus, queue-length=1
          operation=NvMService_AC3_SRBS/WriteBlock, queue-length=1
      PSProxy_Rte_NvmBlock_WhlImbRejctn_RiPeakPrev_Deprecated: provided-interface=NvMService_AC3_SRBS
        provided-com-specs:
          operation=NvMService_AC3_SRBS/EraseBlock, queue-length=1
          operation=NvMService_AC3_SRBS/GetErrorStatus, queue-length=1
          operation=NvMService_AC3_SRBS/InvalidateNvBlock, queue-length=1
          operation=NvMService_AC3_SRBS/ReadBlock, queue-length=1
          operation=NvMService_AC3_SRBS/SetRamBlockStatus, queue-length=1
          operation=NvMService_AC3_SRBS/WriteBlock, queue-length=1
      PSProxy_Rte_NvmBlock_WhlImbRejctn_LePeakPrev_Deprecated: provided-interface=NvMService_AC3_SRBS
        provided-com-specs:
          operation=NvMService_AC3_SRBS/EraseBlock, queue-length=1
          operation=NvMService_AC3_SRBS/GetErrorStatus, queue-length=1
          operation=NvMService_AC3_SRBS/InvalidateNvBlock, queue-length=1
          operation=NvMService_AC3_SRBS/ReadBlock, queue-length=1
          operation=NvMService_AC3_SRBS/SetRamBlockStatus, queue-length=1
          operation=NvMService_AC3_SRBS/WriteBlock, queue-length=1
      PSProxy_Rte_NvmBlock_WhlImbRejctn_ActvCmpBand2_Deprecated: provided-interface=NvMService_AC3_SRBS
        provided-com-specs:
          operation=NvMService_AC3_SRBS/EraseBlock, queue-length=1
          operation=NvMService_AC3_SRBS/GetErrorStatus, queue-length=1
          operation=NvMService_AC3_SRBS/InvalidateNvBlock, queue-length=1
          operation=NvMService_AC3_SRBS/ReadBlock, queue-length=1
          operation=NvMService_AC3_SRBS/SetRamBlockStatus, queue-length=1
          operation=NvMService_AC3_SRBS/WriteBlock, queue-length=1
      PSProxy_Rte_NvmBlock_Bootloader_EcuId: provided-interface=NvMService_AC3_SRBS
        provided-com-specs:
          operation=NvMService_AC3_SRBS/EraseBlock, queue-length=1
          operation=NvMService_AC3_SRBS/GetErrorStatus, queue-length=1
          operation=NvMService_AC3_SRBS/InvalidateNvBlock, queue-length=1
          operation=NvMService_AC3_SRBS/ReadBlock, queue-length=1
          operation=NvMService_AC3_SRBS/SetRamBlockStatus, queue-length=1
          operation=NvMService_AC3_SRBS/WriteBlock, queue-length=1
      PSProxy_Rte_NvmBlock_Bootloader_NbId: provided-interface=NvMService_AC3_SRBS
        provided-com-specs:
          operation=NvMService_AC3_SRBS/EraseBlock, queue-length=1
          operation=NvMService_AC3_SRBS/GetErrorStatus, queue-length=1
          operation=NvMService_AC3_SRBS/InvalidateNvBlock, queue-length=1
          operation=NvMService_AC3_SRBS/ReadBlock, queue-length=1
          operation=NvMService_AC3_SRBS/SetRamBlockStatus, queue-length=1
          operation=NvMService_AC3_SRBS/WriteBlock, queue-length=1
      PSProxy_Rte_NvmBlock_Bootloader_SBAT: provided-interface=NvMService_AC3_SRBS
        provided-com-specs:
          operation=NvMService_AC3_SRBS/EraseBlock, queue-length=1
          operation=NvMService_AC3_SRBS/GetErrorStatus, queue-length=1
          operation=NvMService_AC3_SRBS/InvalidateNvBlock, queue-length=1
          operation=NvMService_AC3_SRBS/ReadBlock, queue-length=1
          operation=NvMService_AC3_SRBS/SetRamBlockStatus, queue-length=1
          operation=NvMService_AC3_SRBS/WriteBlock, queue-length=1
      PSProxy_DemAdminDataBlock: provided-interface=NvMService_AC3_SRBS
        provided-com-specs:
          operation=NvMService_AC3_SRBS/EraseBlock, queue-length=1
          operation=NvMService_AC3_SRBS/GetErrorStatus, queue-length=1
          operation=NvMService_AC3_SRBS/InvalidateNvBlock, queue-length=1
          operation=NvMService_AC3_SRBS/ReadBlock, queue-length=1
          operation=NvMService_AC3_SRBS/SetRamBlockStatus, queue-length=1
          operation=NvMService_AC3_SRBS/WriteBlock, queue-length=1
      PSProxy_DemStatusDataBlock: provided-interface=NvMService_AC3_SRBS
        provided-com-specs:
          operation=NvMService_AC3_SRBS/EraseBlock, queue-length=1
          operation=NvMService_AC3_SRBS/GetErrorStatus, queue-length=1
          operation=NvMService_AC3_SRBS/InvalidateNvBlock, queue-length=1
          operation=NvMService_AC3_SRBS/ReadBlock, queue-length=1
          operation=NvMService_AC3_SRBS/SetRamBlockStatus, queue-length=1
          operation=NvMService_AC3_SRBS/WriteBlock, queue-length=1
      PSProxy_Rte_NvmBlock_CustDiagc_GmIgnCntr: provided-interface=NvMService_AC3_SRBS
        provided-com-specs:
          operation=NvMService_AC3_SRBS/EraseBlock, queue-length=1
          operation=NvMService_AC3_SRBS/GetErrorStatus, queue-length=1
          operation=NvMService_AC3_SRBS/InvalidateNvBlock, queue-length=1
          operation=NvMService_AC3_SRBS/ReadBlock, queue-length=1
          operation=NvMService_AC3_SRBS/SetRamBlockStatus, queue-length=1
          operation=NvMService_AC3_SRBS/WriteBlock, queue-length=1
      PSProxy_Rte_NvmBlock_GmMsg778BusHiSpd_DtcTrigStsAry: provided-interface=NvMService_AC3_SRBS
        provided-com-specs:
          operation=NvMService_AC3_SRBS/EraseBlock, queue-length=1
          operation=NvMService_AC3_SRBS/GetErrorStatus, queue-length=1
          operation=NvMService_AC3_SRBS/InvalidateNvBlock, queue-length=1
          operation=NvMService_AC3_SRBS/ReadBlock, queue-length=1
          operation=NvMService_AC3_SRBS/SetRamBlockStatus, queue-length=1
          operation=NvMService_AC3_SRBS/WriteBlock, queue-length=1
      PSProxy_SnpshtDataAry: provided-interface=NvMService_AC3_SRBS
        provided-com-specs:
          operation=NvMService_AC3_SRBS/EraseBlock, queue-length=1
          operation=NvMService_AC3_SRBS/GetErrorStatus, queue-length=1
          operation=NvMService_AC3_SRBS/InvalidateNvBlock, queue-length=1
          operation=NvMService_AC3_SRBS/ReadBlock, queue-length=1
          operation=NvMService_AC3_SRBS/SetRamBlockStatus, queue-length=1
          operation=NvMService_AC3_SRBS/WriteBlock, queue-length=1
      PSProxy_Rte_NvmBlock_EotLrng_MaxHwAgCwAndCcw_Deprecated: provided-interface=NvMService_AC3_SRBS
        provided-com-specs:
          operation=NvMService_AC3_SRBS/EraseBlock, queue-length=1
          operation=NvMService_AC3_SRBS/GetErrorStatus, queue-length=1
          operation=NvMService_AC3_SRBS/InvalidateNvBlock, queue-length=1
          operation=NvMService_AC3_SRBS/ReadBlock, queue-length=1
          operation=NvMService_AC3_SRBS/SetRamBlockStatus, queue-length=1
          operation=NvMService_AC3_SRBS/WriteBlock, queue-length=1
      PSProxy_Rte_NvmBlock_EotLrng_MaxHwAgCwAndCcw: provided-interface=NvMService_AC3_SRBS
        provided-com-specs:
          operation=NvMService_AC3_SRBS/EraseBlock, queue-length=1
          operation=NvMService_AC3_SRBS/GetErrorStatus, queue-length=1
          operation=NvMService_AC3_SRBS/InvalidateNvBlock, queue-length=1
          operation=NvMService_AC3_SRBS/ReadBlock, queue-length=1
          operation=NvMService_AC3_SRBS/SetRamBlockStatus, queue-length=1
          operation=NvMService_AC3_SRBS/WriteBlock, queue-length=1
      PSProxy_Rte_NvmBlock_WhlImbRejctn_CmpPeakData: provided-interface=NvMService_AC3_SRBS
        provided-com-specs:
          operation=NvMService_AC3_SRBS/EraseBlock, queue-length=1
          operation=NvMService_AC3_SRBS/GetErrorStatus, queue-length=1
          operation=NvMService_AC3_SRBS/InvalidateNvBlock, queue-length=1
          operation=NvMService_AC3_SRBS/ReadBlock, queue-length=1
          operation=NvMService_AC3_SRBS/SetRamBlockStatus, queue-length=1
          operation=NvMService_AC3_SRBS/WriteBlock, queue-length=1
    behavior NvMProxyInternalBehavior
      timing event Timer_NvMProxy_MainFunction: start-on-event=NvMProxy_MainFunction, period=0.01
